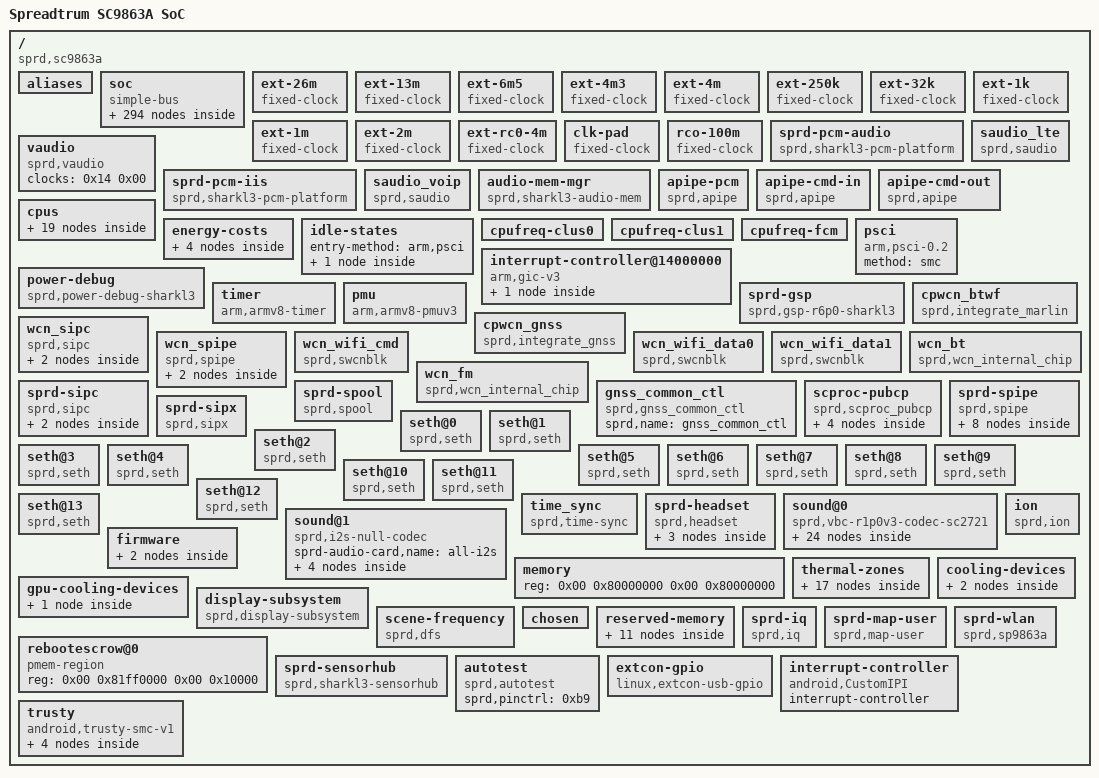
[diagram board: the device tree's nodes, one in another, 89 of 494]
/dts-v1/;

/ {
	interrupt-parent = < 0x01 >;
	#address-cells = < 0x02 >;
	#size-cells = < 0x02 >;
	cpuinfo_hardware = "UNISOC SC9863A";
	model = "Spreadtrum SC9863A SoC";
	compatible = "sprd,sc9863a";
	sprd,sc-id = "sp9863a 1000 1000";

	aliases {
		i2c0 = "/soc/ap-apb/i2c@70500000";
		i2c1 = "/soc/ap-apb/i2c@70600000";
		i2c2 = "/soc/ap-apb/i2c@70700000";
		i2c3 = "/soc/ap-apb/i2c@70800000";
		i2c4 = "/soc/ap-apb/i2c@70900000";
		i2c5 = "/soc/ap-apb/i2c@71500000";
		i2c6 = "/soc/ap-apb/i2c@71600000";
		i2c7 = "/soc/aon/i2c@40080000";
		spi0 = "/soc/ap-apb/spi@70a00000";
		spi1 = "/soc/ap-apb/spi@70b00000";
		spi2 = "/soc/ap-apb/spi@70c00000";
		spi3 = "/soc/ap-apb/spi@71400000";
		spi4 = "/soc/aon/spi@41800000";
		thm-sensor12 = "/soc/aon/test-sensor@12";
		seth0 = "/seth@0";
		seth1 = "/seth@1";
		seth2 = "/seth@2";
		seth3 = "/seth@3";
		seth4 = "/seth@4";
		seth5 = "/seth@5";
		seth6 = "/seth@6";
		seth7 = "/seth@7";
		seth8 = "/seth@8";
		seth9 = "/seth@9";
		seth10 = "/seth@10";
		seth11 = "/seth@11";
		seth12 = "/seth@12";
		seth13 = "/seth@13";
		cooling-device0 = "/cooling-devices/cluster0-cooling";
		cooling-device1 = "/cooling-devices/cluster1-cooling";
		gpu-cooling0 = "/gpu-cooling-devices/gpu-cooling0";
		thm-sensor11 = "/thermal-zones/cpu-thmzone";
		serial0 = "/soc/ap-apb/serial@70000000";
		serial1 = "/soc/ap-apb/serial@70100000";
	};

	soc {
		compatible = "simple-bus";
		#address-cells = < 0x02 >;
		#size-cells = < 0x02 >;
		ranges;
		phandle = < 0xbd >;

		modem-dbg-log@1000c000 {
			compatible = "sprd,dbg-log-sharkl3";
			reg = < 0x00 0x1000c000 0x00 0x4000 >;
			sprd,syscon-aon-apb = < 0x02 >;
			sprd,syscon-dsi-apb = < 0x03 >;
			sprd,syscon-pll-apb = < 0x04 >;
			sprd,ch-name = "TRAINING\0WTL\0MDAR\0TPIU\0DBUS\0WCN";
			sprd,ch-index = < 0x0f 0x01 0x00 0x02 0x03 0x04 >;
			sprd,dcfix;
			sprd,mm;
			status = "okay";
			clock-names = "serdes_eb\0src0\0src1\0src2";
			clocks = < 0x05 0x68 0x06 0x00 0x06 0x18 0x06 0x14 >;
			phandle = < 0xbe >;
		};

		syscon@20e00000 {
			compatible = "syscon";
			#syscon-cells = < 0x02 >;
			reg = < 0x00 0x20e00000 0x00 0x10000 >;
			phandle = < 0x0e >;
		};

		syscon@300e0000 {
			compatible = "syscon";
			#syscon-cells = < 0x02 >;
			reg = < 0x00 0x300e0000 0x00 0x10000 >;
			phandle = < 0x99 >;
		};

		syscon@300f0000 {
			compatible = "syscon";
			#syscon-cells = < 0x02 >;
			reg = < 0x00 0x300f0000 0x00 0x10000 >;
			phandle = < 0x52 >;
		};

		mailbox@400a0000 {
			compatible = "sprd,mailbox";
			reg = < 0x00 0x400a0000 0x00 0x8000 0x00 0x400a8000 0x00 0x8000 >;
			syscons = < 0x02 0x04 0x200000 >;
			syscon-names = "clk";
			interrupts = < 0x00 0x44 0x04 0x00 0x45 0x04 0x00 0x77 0x04 >;
			sprd,sensor = < 0x07 >;
			sprd,core-cnt = < 0x08 >;
			sprd,version = < 0x102 >;
			phandle = < 0xbf >;
		};

		syscon@40200000 {
			compatible = "syscon";
			#syscon-cells = < 0x02 >;
			reg = < 0x00 0x40200000 0x00 0x10000 >;
			phandle = < 0xc0 >;
		};

		syscon@402b0000 {
			compatible = "syscon";
			#syscon-cells = < 0x02 >;
			reg = < 0x00 0x402b0000 0x00 0x10000 >;
			phandle = < 0x07 >;
		};

		power-domain@402b0058 {
			compatible = "sprd,sharkl3-disp-domain";
			reg = < 0x00 0x402b0058 0x00 0x20 >;
			syscons = < 0x07 0x58 0x2000000 >;
			syscon-names = "power";
			#power-domain-cells = < 0x00 >;
			phandle = < 0x3f >;
		};

		syscon@402e0000 {
			compatible = "syscon";
			#syscon-cells = < 0x02 >;
			reg = < 0x00 0x402e0000 0x00 0x10000 >;
			phandle = < 0x02 >;
		};

		syscon@40350000 {
			compatible = "syscon";
			#syscon-cells = < 0x02 >;
			reg = < 0x00 0x40350000 0x00 0x3000 >;
			phandle = < 0x03 >;
		};

		syscon@40353000 {
			compatible = "syscon";
			#syscon-cells = < 0x02 >;
			reg = < 0x00 0x40353000 0x00 0x6000 >;
			phandle = < 0x04 >;
		};

		syscon@40359000 {
			compatible = "syscon";
			#syscon-cells = < 0x02 >;
			reg = < 0x00 0x40359000 0x00 0x3000 >;
			phandle = < 0x0f >;
		};

		syscon@4035c000 {
			compatible = "syscon";
			#syscon-cells = < 0x02 >;
			reg = < 0x00 0x4035c000 0x00 0x3000 >;
			phandle = < 0x54 >;
		};

		syscon@40363000 {
			compatible = "syscon";
			#syscon-cells = < 0x02 >;
			reg = < 0x00 0x40363000 0x00 0x3000 >;
			phandle = < 0x18 >;
		};

		syscon@40366000 {
			compatible = "syscon";
			#syscon-cells = < 0x02 >;
			reg = < 0x00 0x40366000 0x00 0x3000 >;
			phandle = < 0x9a >;
		};

		syscon@403a0000 {
			compatible = "syscon";
			#syscon-cells = < 0x02 >;
			reg = < 0x00 0x403a0000 0x00 0x10000 >;
			phandle = < 0x9b >;
		};

		syscon@60800000 {
			compatible = "syscon";
			#syscon-cells = < 0x02 >;
			reg = < 0x00 0x60800000 0x00 0x10000 >;
			phandle = < 0x4a >;
		};

		syscon@62000000 {
			compatible = "syscon";
			#syscon-cells = < 0x02 >;
			reg = < 0x00 0x62000000 0x00 0x10000 >;
			phandle = < 0x41 >;
		};

		syscon@71300000 {
			compatible = "syscon";
			#syscon-cells = < 0x02 >;
			reg = < 0x00 0x71300000 0x00 0x40000 >;
			phandle = < 0x0b >;
		};

		syscon@40500000 {
			compatible = "syscon";
			#syscon-cells = < 0x02 >;
			reg = < 0x00 0x40500000 0x00 0x10000 >;
			phandle = < 0x92 >;
		};

		syscon@40510000 {
			compatible = "syscon";
			#syscon-cells = < 0x02 >;
			reg = < 0x00 0x40510000 0x00 0x10000 >;
			phandle = < 0x93 >;
		};

		syscon@40520000 {
			compatible = "syscon";
			#syscon-cells = < 0x02 >;
			reg = < 0x00 0x40520000 0x00 0x10000 >;
			phandle = < 0x94 >;
		};

		syscon@40530000 {
			compatible = "syscon";
			#syscon-cells = < 0x02 >;
			reg = < 0x00 0x40530000 0x00 0x10000 >;
			phandle = < 0x95 >;
		};

		syscon@40540000 {
			compatible = "syscon";
			#syscon-cells = < 0x02 >;
			reg = < 0x00 0x40540000 0x00 0x10000 >;
			phandle = < 0x96 >;
		};

		syscon@40550000 {
			compatible = "syscon";
			#syscon-cells = < 0x02 >;
			reg = < 0x00 0x40550000 0x00 0x10000 >;
			phandle = < 0x97 >;
		};

		ap-apb {
			compatible = "simple-bus";
			#address-cells = < 0x01 >;
			#size-cells = < 0x01 >;
			ranges;

			serial@70000000 {
				compatible = "sprd,sc9863-uart\0sprd,sc9836-uart";
				reg = < 0x70000000 0x100 >;
				interrupts = < 0x00 0x02 0x04 >;
				clock-names = "enable\0uart\0source";
				clocks = < 0x08 0x0c 0x09 0x09 0x0a >;
				status = "okay";
				phandle = < 0xc1 >;
			};

			serial@70100000 {
				compatible = "sprd,sc9863-uart\0sprd,sc9836-uart";
				reg = < 0x70100000 0x100 >;
				interrupts = < 0x00 0x03 0x04 >;
				clock-names = "enable\0uart\0source";
				clocks = < 0x08 0x0d 0x09 0x0a 0x0a >;
				status = "okay";
				phandle = < 0xc2 >;
			};

			serial@70200000 {
				compatible = "sprd,sc9863-uart\0sprd,sc9836-uart";
				reg = < 0x70200000 0x100 >;
				interrupts = < 0x00 0x04 0x04 >;
				clock-names = "enable\0uart\0source";
				clocks = < 0x08 0x0e 0x09 0x0b 0x0a >;
				status = "disabled";
				phandle = < 0xc3 >;
			};

			serial@70300000 {
				compatible = "sprd,sc9863-uart\0sprd,sc9836-uart";
				reg = < 0x70300000 0x100 >;
				interrupts = < 0x00 0x05 0x04 >;
				clock-names = "enable\0uart\0source";
				clocks = < 0x08 0x0f 0x09 0x0c 0x0a >;
				status = "disabled";
				phandle = < 0xc4 >;
			};

			serial@70400000 {
				compatible = "sprd,sc9863-uart\0sprd,sc9836-uart";
				reg = < 0x70400000 0x100 >;
				interrupts = < 0x00 0x06 0x04 >;
				clock-names = "enable\0uart\0source";
				clocks = < 0x08 0x10 0x09 0x0d 0x0a >;
				status = "disabled";
				phandle = < 0xc5 >;
			};

			i2c@70500000 {
				compatible = "sprd,sharkl3-i2c";
				reg = < 0x70500000 0x1000 >;
				interrupts = < 0x00 0x0b 0x04 >;
				clock-names = "enable\0i2c\0source";
				clock-frequency = < 0x186a0 >;
				#address-cells = < 0x01 >;
				#size-cells = < 0x00 >;
				status = "disabled";
				syscon-names = "i2c_rst";
				syscons = < 0x0b 0x04 0x100 >;
				clocks = < 0x08 0x07 0x09 0x0e 0x0a >;
				phandle = < 0xc6 >;
			};

			i2c@70600000 {
				compatible = "sprd,sharkl3-i2c";
				reg = < 0x70600000 0x1000 >;
				interrupts = < 0x00 0x0c 0x04 >;
				clock-names = "enable\0i2c\0source";
				clock-frequency = < 0x186a0 >;
				#address-cells = < 0x01 >;
				#size-cells = < 0x00 >;
				status = "disabled";
				syscon-names = "i2c_rst";
				syscons = < 0x0b 0x04 0x200 >;
				clocks = < 0x08 0x08 0x09 0x0f 0x0a >;
				phandle = < 0xc7 >;
			};

			i2c@70700000 {
				compatible = "sprd,sharkl3-i2c";
				reg = < 0x70700000 0x1000 >;
				interrupts = < 0x00 0x0d 0x04 >;
				clock-names = "enable\0i2c\0source";
				clock-frequency = < 0x186a0 >;
				#address-cells = < 0x01 >;
				#size-cells = < 0x00 >;
				status = "disabled";
				syscon-names = "i2c_rst";
				syscons = < 0x0b 0x04 0x400 >;
				clocks = < 0x08 0x09 0x09 0x10 0x0a >;
				phandle = < 0xc8 >;
			};

			i2c@70800000 {
				compatible = "sprd,sharkl3-i2c";
				reg = < 0x70800000 0x1000 >;
				interrupts = < 0x00 0x0e 0x04 >;
				clock-names = "enable\0i2c\0source";
				clock-frequency = < 0x61a80 >;
				#address-cells = < 0x01 >;
				#size-cells = < 0x00 >;
				status = "disabled";
				syscon-names = "i2c_rst";
				syscons = < 0x0b 0x04 0x800 >;
				clocks = < 0x08 0x0a 0x09 0x11 0x0a >;
				phandle = < 0xc9 >;
			};

			i2c@70900000 {
				compatible = "sprd,sharkl3-i2c";
				reg = < 0x70900000 0x1000 >;
				interrupts = < 0x00 0x0f 0x04 >;
				clock-names = "enable\0i2c\0source";
				clock-frequency = < 0x186a0 >;
				#address-cells = < 0x01 >;
				#size-cells = < 0x00 >;
				status = "disabled";
				syscon-names = "i2c_rst";
				syscons = < 0x0b 0x04 0x1000 >;
				clocks = < 0x08 0x0b 0x09 0x12 0x0a >;
				phandle = < 0xca >;
			};

			spi@70a00000 {
				compatible = "sprd,sc9863-spi";
				reg = < 0x70a00000 0x1000 >;
				interrupts = < 0x00 0x07 0x04 >;
				#address-cells = < 0x01 >;
				#size-cells = < 0x00 >;
				status = "okay";
				clock-names = "enable\0spi\0source";
				clocks = < 0x08 0x04 0x09 0x15 0x06 0x03 >;
				phandle = < 0xcb >;
			};

			spi@70b00000 {
				compatible = "sprd,sc9863-spi";
				reg = < 0x70b00000 0x1000 >;
				interrupts = < 0x00 0x08 0x04 >;
				#address-cells = < 0x01 >;
				#size-cells = < 0x00 >;
				status = "disabled";
				clock-names = "enable\0spi\0source";
				clocks = < 0x08 0x05 0x09 0x16 0x06 0x03 >;
				phandle = < 0xcc >;
			};

			spi@70c00000 {
				compatible = "sprd,sc9863-spi";
				reg = < 0x70c00000 0x1000 >;
				interrupts = < 0x00 0x09 0x04 >;
				#address-cells = < 0x01 >;
				#size-cells = < 0x00 >;
				status = "disabled";
				clock-names = "enable\0spi\0source";
				clocks = < 0x08 0x06 0x09 0x17 0x06 0x03 >;
				phandle = < 0xcd >;
			};

			i2s@70d00000 {
				compatible = "sprd,i2s";
				reg = < 0x70d00000 0x100000 >;
				sprd,dai_name = "i2s_bt_sco0";
				sprd,hw_port = < 0x00 >;
				sprd,syscon-ap-apb = < 0x0b >;
				#sound-dai-cells = < 0x00 >;
				status = "okay";
				clock-names = "clk_iis0\0clk_twpll_128m\0clk_twpll_153m6";
				clocks = < 0x09 0x19 0x06 0x0a 0x06 0x0f >;
				sprd,config_type = "pcm";
				sprd,slave_timeout = < 0xf11 >;
				sprd,_hw_port = < 0x00 >;
				sprd,fs = < 0x1f40 >;
				sprd,bus_type = < 0x01 >;
				sprd,rtx_mode = < 0x03 >;
				sprd,byte_per_chan = < 0x01 >;
				sprd,slave_mode = < 0x00 >;
				sprd,lsb = < 0x00 >;
				sprd,lrck = < 0x00 >;
				sprd,low_for_left = < 0x01 >;
				sprd,clk_inv = < 0x00 >;
				sprd,pcm_short_frame = < 0x01 >;
				sprd,pcm_slot = < 0x01 >;
				sprd,pcm_cycle = < 0x01 >;
				sprd,tx_watermark = < 0x0c >;
				sprd,rx_watermark = < 0x14 >;
				phandle = < 0xae >;
			};

			spi@71400000 {
				compatible = "sprd,sc9863-spi";
				reg = < 0x71400000 0x1000 >;
				interrupts = < 0x00 0x13 0x04 >;
				#address-cells = < 0x01 >;
				#size-cells = < 0x00 >;
				status = "disabled";
				clock-names = "enable\0spi\0source";
				clocks = < 0x08 0x12 0x09 0x18 0x06 0x03 >;
				phandle = < 0xce >;
			};

			i2c@71500000 {
				compatible = "sprd,sharkl3-i2c";
				reg = < 0x71500000 0x1000 >;
				interrupts = < 0x00 0x74 0x04 >;
				clock-names = "enable\0i2c\0source";
				clock-frequency = < 0x186a0 >;
				#address-cells = < 0x01 >;
				#size-cells = < 0x00 >;
				status = "disabled";
				syscon-names = "i2c_rst";
				syscons = < 0x0b 0x04 0x100000 >;
				clocks = < 0x08 0x13 0x09 0x13 0x0a >;
				phandle = < 0xcf >;
			};

			i2c@71600000 {
				compatible = "sprd,sharkl3-i2c";
				reg = < 0x71600000 0x1000 >;
				interrupts = < 0x00 0x75 0x04 >;
				clock-names = "enable\0i2c\0source";
				clock-frequency = < 0x186a0 >;
				#address-cells = < 0x01 >;
				#size-cells = < 0x00 >;
				status = "disabled";
				syscon-names = "i2c_rst";
				syscons = < 0x0b 0x04 0x200000 >;
				clocks = < 0x08 0x14 0x09 0x14 0x0a >;
				phandle = < 0xd0 >;
			};
		};

		ap-ahb {
			compatible = "simple-bus";
			#address-cells = < 0x01 >;
			#size-cells = < 0x01 >;
			ranges;

			dma-controller@20100000 {
				compatible = "sprd,sharkl3-dma";
				reg = < 0x20100000 0x4000 >;
				interrupts = < 0x00 0x32 0x04 >;
				#dma-cells = < 0x01 >;
				#dma-channels = < 0x1c >;
				clock-names = "enable";
				clocks = < 0x0c 0x01 >;
				phandle = < 0x83 >;
			};

			usb@20200000 {
				compatible = "sprd,sharkl3-musb";
				reg = < 0x20200000 0x2000 >;
				interrupts = < 0x00 0x37 0x04 >;
				interrupt-names = "mc";
				clocks = < 0x0c 0x00 >;
				clock-names = "core_clk";
				phy-type = "usb20_sprd_phy";
				usb-phy = < 0x0d >;
				phy-names = "usb";
				dr-mode = "peripheral";
				phandle = < 0xd1 >;
			};

			hsphy@20e00000 {
				compatible = "sprd,sharkl3-phy";
				reg = < 0x20e00000 0x3030 >;
				reg-names = "phy_glb_regs";
				sprd,syscon-enable = < 0x02 >;
				sprd,syscon-apahb = < 0x0e >;
				sprd,syscon-anag4 = < 0x0f >;
				sprd,vdd-voltage = < 0x2e8a10 >;
				io-channels = < 0x10 0x1e 0x10 0x1f >;
				io-channel-names = "dp\0dm";
				#phy-cells = < 0x00 >;
				vdd-supply = < 0x11 >;
				extcon = < 0x12 >;
				phandle = < 0x0d >;
			};

			sdio@20600000 {
				compatible = "sprd,sdhc-r11p1";
				reg = < 0x20600000 0x1000 >;
				interrupts = < 0x00 0x3c 0x04 >;
				status = "okay";
				clock-names = "sdio_clk\0sdio_clk_source\0sdio_ahb_enable";
				clocks = < 0x13 0x21 0x14 0x02 0x0c 0x07 >;
				sprd,hs400es-dly = < 0x55 0x7f 0x38 0x38 >;
				sprd,hs400-dly = < 0x55 0xd3 0x35 0x35 >;
				sprd,hs200-dly = < 0x7f 0xcd 0xcd 0xcd >;
				sprd,ddr52-dly = < 0x32 0x23 0x18 0x18 >;
				sprd,mmchs-dly = < 0x00 0x35 0x35 0x35 >;
				vmmc-supply = < 0x15 >;
				voltage-ranges = < 0xbb8 0xbb8 >;
				bus-width = < 0x08 >;
				non-removable;
				cap-mmc-hw-reset;
				mmc-hs400-enhanced-strobe;
				mmc-hs400-1_8v;
				mmc-hs200-1_8v;
				mmc-ddr-1_8v;
				sprd,name = "sdio_emmc";
				sprd,sdio-adma;
				no-sdio;
				no-sd;
				phandle = < 0xd2 >;
			};

			sdio@20300000 {
				compatible = "sprd,sdhc-r11p1";
				reg = < 0x20300000 0x1000 >;
				interrupts = < 0x00 0x39 0x04 >;
				status = "okay";
				clock-names = "sdio_clk\0sdio_clk_source\0sdio_ahb_enable";
				clocks = < 0x13 0x1e 0x14 0x02 0x0c 0x04 >;
				sprd,sdr104-dly = < 0x7f 0x3d 0xc5 0xc5 >;
				sprd,sdr50-dly = < 0x7f 0x7f 0x4c 0x4c >;
				sprd,sdhs-dly = < 0x7f 0x32 0x83 0x83 >;
				vmmc-supply = < 0x16 >;
				vqmmc-supply = < 0x17 >;
				voltage-ranges = < 0xbb8 0xbb8 >;
				bus-width = < 0x04 >;
				sd-uhs-sdr104;
				sd-uhs-sdr50;
				sprd,name = "sdio_sd";
				sprd,sdio-adma;
				no-sdio;
				no-mmc;
				phandle = < 0xd3 >;
			};
		};

		aon {
			compatible = "simple-bus";
			#address-cells = < 0x01 >;
			#size-cells = < 0x01 >;
			ranges;

			audio-codec@40000000 {
				compatible = "sprd,sharkl3-audio-codec";
				reg = < 0x40000000 0x2000 >;
				interrupts = < 0x00 0x14 0x00 >;
				sprd,syscon-aon-apb = < 0x02 >;
				sprd,anlg-phy-g-syscon = < 0x18 >;
				phandle = < 0x3d >;
			};

			vbc@40020000 {
				compatible = "sprd,vbc-r1p0v3";
				#sound-dai-cells = < 0x01 >;
				reg = < 0x40020000 0x10000 >;
				sprd,clk-stable = < 0x402d0060 0x04 >;
				sprd,syscon-aon-apb = < 0x02 >;
				sprd,syscon-pmu-apb = < 0x07 >;
				sprd,dynamic-eq-support = < 0x00 >;
				sprd,vbc-iis-lr-invert = < 0x00 0x01 0x01 >;
				sprd,vbc-use-dma-type = < 0x00 0x00 0x00 0x00 >;
				sprd,vbc-use-ad01-only = < 0x01 >;
				sprd,iis_bt_fm_loop = < 0x03 0x04 >;
				pinctrl-names = "vbc_iis1_0\0ap_iis0_0\0ap_iis1_0\0tgdsp_iis0_0\0tgdsp_iis1_0\0pubcp_iis0_0\0vbc_iis1_3\0ap_iis0_3\0tgdsp_iis0_3\0tgdsp_iis1_3\0pubcp_iis0_3\0wcn_iis0_3\0vbc_iis1_4\0ap_iis0_4\0tgdsp_iis0_4\0tgdsp_iis1_4\0pubcp_iis0_4\0wcn_iis0_4\0iis_bt_fm_loop_3_4_enable\0iis_bt_fm_loop_3_4_disable";
				pinctrl-0 = < 0x19 >;
				pinctrl-1 = < 0x1a >;
				pinctrl-2 = < 0x1b >;
				pinctrl-3 = < 0x1c >;
				pinctrl-4 = < 0x1d >;
				pinctrl-5 = < 0x1e >;
				pinctrl-6 = < 0x1f >;
				pinctrl-7 = < 0x20 >;
				pinctrl-8 = < 0x21 >;
				pinctrl-9 = < 0x22 >;
				pinctrl-10 = < 0x23 >;
				pinctrl-11 = < 0x24 >;
				pinctrl-12 = < 0x25 >;
				pinctrl-13 = < 0x26 >;
				pinctrl-14 = < 0x27 >;
				pinctrl-15 = < 0x28 >;
				pinctrl-16 = < 0x29 >;
				pinctrl-17 = < 0x2a >;
				pinctrl-18 = < 0x2b >;
				pinctrl-19 = < 0x2c >;
				phandle = < 0xaa >;
			};

			dma-controller@40100000 {
				compatible = "sprd,sharkl3-dma";
				reg = < 0x40100000 0x4000 >;
				#dma-cells = < 0x01 >;
				#dma-channels = < 0x09 >;
				clock-names = "enable";
				clocks = < 0x05 0x32 >;
				phandle = < 0x82 >;
			};

			gpio@40210000 {
				compatible = "sprd,sharkl3-eic-debounce";
				reg = < 0x40210000 0x80 0x40370000 0x80 >;
				gpio-controller;
				#gpio-cells = < 0x02 >;
				interrupt-controller;
				#interrupt-cells = < 0x02 >;
				interrupts = < 0x00 0x25 0x04 >;
				phandle = < 0xba >;
			};

			gpio@40210080 {
				compatible = "sprd,sharkl3-eic-latch";
				reg = < 0x40210080 0x20 0x40370080 0x20 >;
				gpio-controller;
				#gpio-cells = < 0x02 >;
				interrupt-controller;
				#interrupt-cells = < 0x02 >;
				interrupts = < 0x00 0x25 0x04 >;
				phandle = < 0xd4 >;
			};

			gpio@402100a0 {
				compatible = "sprd,sharkl3-eic-async";
				reg = < 0x402100a0 0x20 0x403700a0 0x20 >;
				gpio-controller;
				#gpio-cells = < 0x02 >;
				interrupt-controller;
				#interrupt-cells = < 0x02 >;
				interrupts = < 0x00 0x25 0x04 >;
				phandle = < 0xd5 >;
			};

			gpio@402100c0 {
				compatible = "sprd,sharkl3-eic-sync";
				reg = < 0x402100c0 0x20 0x403700c0 0x20 >;
				gpio-controller;
				#gpio-cells = < 0x02 >;
				interrupt-controller;
				#interrupt-cells = < 0x02 >;
				interrupts = < 0x00 0x25 0x04 >;
				phandle = < 0xd6 >;
			};

			timer@40230000 {
				compatible = "sprd,syst-timer";
				reg = < 0x40230000 0x10 >;
				clocks = < 0x2d >;
				phandle = < 0xd7 >;
			};

			timer@40040000 {
				compatible = "sprd,sysfrt-timer";
				reg = < 0x40040000 0x10 >;
				clocks = < 0x2e >;
				phandle = < 0xd8 >;
			};

			timer@40050000 {
				compatible = "sprd,sharkl3-timer";
				reg = < 0x40050000 0x14 >;
				interrupts = < 0x00 0x1b 0x04 >;
				clocks = < 0x2e >;
			};

			timer@40050020 {
				compatible = "sprd,sharkl3-suspend-timer";
				reg = < 0x40050020 0x14 >;
				interrupts = < 0x00 0x1c 0x04 >;
				clocks = < 0x2e >;
			};

			efuse@40240000 {
				compatible = "sprd,sharkl3-efuse";
				reg = < 0x40240000 0x10000 >;
				clock-names = "enable";
				hwlocks = < 0x2f 0x08 >;
				clocks = < 0x05 0x0d >;
				phandle = < 0xd9 >;

				gthm-delta@21 {
					reg = < 0x21 0x04 >;
					bits = < 0x01 0x07 >;
					phandle = < 0x30 >;
				};

				cthm-sign@22 {
					reg = < 0x22 0x04 >;
					bits = < 0x00 0x01 >;
					phandle = < 0x31 >;
				};

				cthm-ratio@22 {
					reg = < 0x22 0x04 >;
					bits = < 0x01 0x07 >;
					phandle = < 0x32 >;
				};

				cthm-delta@23 {
					reg = < 0x23 0x04 >;
					bits = < 0x00 0x07 >;
					phandle = < 0x33 >;
				};

				wcn-alpha@14 {
					reg = < 0x14 0x04 >;
					phandle = < 0x9f >;
				};

				wcn-beta@18 {
					reg = < 0x18 0x04 >;
					phandle = < 0xa0 >;
				};

				wcn-gamma@1c {
					reg = < 0x1c 0x04 >;
					phandle = < 0xa1 >;
				};

				wcn-delta@20 {
					reg = < 0x20 0x04 >;
					phandle = < 0xa2 >;
				};

				dvfs-bin-dsu@a {
					reg = < 0x0a 0x04 >;
					bits = < 0x04 0x04 >;
					phandle = < 0x91 >;
				};

				dvfs-bin-cpu0@9 {
					reg = < 0x09 0x04 >;
					bits = < 0x00 0x04 >;
					phandle = < 0x8d >;
				};

				dvfs-bin-cpu1@9 {
					reg = < 0x09 0x04 >;
					bits = < 0x04 0x04 >;
					phandle = < 0x8f >;
				};
			};

			pwm@40260000 {
				compatible = "sprd,sharkl3-pwm\0sprd,sharkl5-pwm";
				reg = < 0x40260000 0x10000 >;
				clock-names = "clk_parent\0clk_pwm0\0clk_pwm0_eb\0clk_pwm1\0clk_pwm1_eb\0clk_pwm2\0clk_pwm2_eb";
				clocks = < 0x0a 0x13 0x0f 0x05 0x04 0x13 0x10 0x05 0x05 0x13 0x11 0x05 0x06 >;
				#pwm-cells = < 0x02 >;
				phandle = < 0xda >;
			};

			pinctrl@402a0000 {
				compatible = "sprd,sharkl3-pinctrl";
				reg = < 0x402a0000 0x10000 >;
				phandle = < 0xb9 >;

				iismtx-inf0-8 {
					pins = "SHARKL3_IIS_INF0_SYS_SEL";
					sprd,control = < 0x08 >;
					phandle = < 0x19 >;
				};

				iismtx-inf0-0 {
					pins = "SHARKL3_IIS_INF0_SYS_SEL";
					sprd,control = < 0x00 >;
					phandle = < 0x1a >;
				};

				iismtx-inf0-1 {
					pins = "SHARKL3_IIS_INF0_SYS_SEL";
					sprd,control = < 0x01 >;
					phandle = < 0x1b >;
				};

				iismtx-inf0-4 {
					pins = "SHARKL3_IIS_INF0_SYS_SEL";
					sprd,control = < 0x04 >;
					phandle = < 0x1c >;
				};

				iismtx-inf0-5 {
					pins = "SHARKL3_IIS_INF0_SYS_SEL";
					sprd,control = < 0x05 >;
					phandle = < 0x1d >;
				};

				iismtx-inf0-3 {
					pins = "SHARKL3_IIS_INF0_SYS_SEL";
					sprd,control = < 0x03 >;
					phandle = < 0x1e >;
				};

				iismtx-inf3-8 {
					pins = "SHARKL3_IIS_INF3_SYS_SEL";
					sprd,control = < 0x08 >;
					phandle = < 0x1f >;
				};

				iismtx-inf3-0 {
					pins = "SHARKL3_IIS_INF3_SYS_SEL";
					sprd,control = < 0x00 >;
					phandle = < 0x20 >;
				};

				iismtx-inf3-4 {
					pins = "SHARKL3_IIS_INF3_SYS_SEL";
					sprd,control = < 0x04 >;
					phandle = < 0x21 >;
				};

				iismtx-inf3-5 {
					pins = "SHARKL3_IIS_INF3_SYS_SEL";
					sprd,control = < 0x05 >;
					phandle = < 0x22 >;
				};

				iismtx-inf3-3 {
					pins = "SHARKL3_IIS_INF3_SYS_SEL";
					sprd,control = < 0x03 >;
					phandle = < 0x23 >;
				};

				iismtx-inf3-11 {
					pins = "SHARKL3_IIS_INF3_SYS_SEL";
					sprd,control = < 0x0b >;
					phandle = < 0x24 >;
				};

				iismtx-inf4-8 {
					pins = "SHARKL3_IIS_INF4_SYS_SEL";
					sprd,control = < 0x08 >;
					phandle = < 0x25 >;
				};

				iismtx-inf4-0 {
					pins = "SHARKL3_IIS_INF4_SYS_SEL";
					sprd,control = < 0x00 >;
					phandle = < 0x26 >;
				};

				iismtx-inf4-4 {
					pins = "SHARKL3_IIS_INF4_SYS_SEL";
					sprd,control = < 0x04 >;
					phandle = < 0x27 >;
				};

				iismtx-inf4-5 {
					pins = "SHARKL3_IIS_INF4_SYS_SEL";
					sprd,control = < 0x05 >;
					phandle = < 0x28 >;
				};

				iismtx-inf4-3 {
					pins = "SHARKL3_IIS_INF4_SYS_SEL";
					sprd,control = < 0x03 >;
					phandle = < 0x29 >;
				};

				iismtx-inf4-11 {
					pins = "SHARKL3_IIS_INF4_SYS_SEL";
					sprd,control = < 0x0b >;
					phandle = < 0x2a >;
				};

				iismtx-inf3-inf4-loop-1 {
					pins = "SHARKL3_IIS_INF4_INF3_LOOP";
					sprd,control = < 0x01 >;
					phandle = < 0x2b >;
				};

				iismtx-inf3-inf4-loop-0 {
					pins = "SHARKL3_IIS_INF4_INF3_LOOP";
					sprd,control = < 0x00 >;
					phandle = < 0x2c >;
				};
			};

			gpio-controller@402c0000 {
				compatible = "sprd,sharkl3-gpio-plus";
				reg = < 0x402c0000 0x1000 >;
				gpio-controller;
				#gpio-cells = < 0x02 >;
				interrupt-controller;
				#interrupt-cells = < 0x02 >;
				interrupts = < 0x00 0x82 0x04 >;
				phandle = < 0xa8 >;
			};

			gpu-thm@402f0000 {
				compatible = "sprd,sharkl3-thermal";
				reg = < 0x402f0000 0x10000 >;
				clock-names = "enable";
				clocks = < 0x05 0x20 >;
				#thermal-sensor-cells = < 0x01 >;
				sprd,algor_ver = < 0x02 >;
				nvmem-cells = < 0x30 >;
				nvmem-cell-names = "thm_delta_cal";
				phandle = < 0xb3 >;
			};

			cpu-thm@40390000 {
				compatible = "sprd,sharkl3-thermal";
				reg = < 0x40390000 0x10000 >;
				clock-names = "enable";
				clocks = < 0x05 0x20 >;
				#thermal-sensor-cells = < 0x01 >;
				sprd,algor_ver = < 0x01 >;
				nvmem-cells = < 0x31 0x32 0x33 >;
				nvmem-cell-names = "thm_sign_cal\0thm_ratio_cal\0thm_delta_cal";
				phandle = < 0xaf >;
			};

			test-sensor@12 {
				compatible = "sprd,virtual-thermal";
				#thermal-sensor-cells = < 0x01 >;
				sensor-names = "test-thmzone";
				phandle = < 0xb4 >;
			};

			hwspinlock@40060000 {
				compatible = "sprd,hwspinlock-r3p0";
				reg = < 0x40060000 0x10000 >;
				#hwlock-cells = < 0x01 >;
				clock-names = "enable";
				clocks = < 0x05 0x16 >;
				phandle = < 0x2f >;
			};

			i2c@40080000 {
				compatible = "sprd,sharkl3-hw-i2c";
				reg = < 0x40080000 0x1000 >;
				interrupts = < 0x00 0x22 0x04 >;
				clock-names = "enable\0i2c\0source\0clk_hw_i2c";
				clock-frequency = < 0x61a80 >;
				#address-cells = < 0x01 >;
				#size-cells = < 0x00 >;
				status = "okay";
				phandle = < 0xdb >;

				regulator@60 {
					compatible = "fcs,fan53555";
					reg = < 0x60 >;
					regulator-name = "fan53555";
					regulator-min-microvolt = < 0x93378 >;
					regulator-max-microvolt = < 0x1587b8 >;
					regulator-ramp-delay = < 0xfa00 >;
					regulator-always-on;
					fcs,suspend-voltage-selector = < 0x01 >;
					phandle = < 0x84 >;
				};
			};

			hwdvfs@40300000 {
				compatible = "sprd,sharkl3-hwdvfs";
				sprd,syscon-enable = < 0x02 >;
				sprd,anlg-phy-g4-ctrl = < 0x0f >;
				sprd,syscon-pmu-apb = < 0x07 >;
				reg = < 0x40300000 0x1000 >;
				interrupts = < 0x00 0x79 0x04 >;
				phandle = < 0xdc >;
			};

			sprd-swdvfs {
				compatible = "sprd,sharkl3-swdvfs";
				phandle = < 0xdd >;
			};

			watchdog@40310000 {
				compatible = "sprd,wdt-r2p0-fiq-sharkl3";
				reg = < 0x40310000 0x1000 >;
				interrupts = < 0x00 0x7c 0x04 >;
				timeout-sec = < 0x1e >;
				clock-names = "enable\0rtc_enable";
				clocks = < 0x05 0x26 0x05 0x42 >;
			};

			djtag@40340000 {
				compatible = "sprd,djtag";
				reg = < 0x40340000 0x1000 >;
				syscon-names = "soft_rst";
				syscons = < 0x02 0x130 0x80 >;
				clock-names = "enable\0tck";
				clocks = < 0x05 0x30 0x05 0x29 >;
				hwlocks = < 0x2f 0x0a >;
				hwlock-names = "djtag";
				#address-cells = < 0x01 >;
				#size-cells = < 0x00 >;
				phandle = < 0xde >;

				aon-busmonitor@3 {
					compatible = "sprd,sharkl3-busmonitor";
					interrupts = < 0x00 0x5c 0x04 >;
					reg = < 0x03 >;
					sprd,bm-num = < 0x07 >;
					sprd,bm-name = "AP\0WTLCP\0PUBCP\0SP\0DMA\0EAXI\0WCN";
					sprd,bm-type = < 0x01 0x01 0x01 0x01 0x01 0x01 0x01 >;
					sprd,bm-dap = < 0x00 0x02 0x01 0x03 0x04 0x05 0x09 >;
					sprd,bm-config = < 0x00 0x01 0x01 0x00 0x01 0x01 0x00 0x01 0x01 0x00 0x01 0x01 0x00 0x01 0x01 0x00 0x01 0x01 0x00 0x01 0x01 >;
					sprd,bm-id = < 0x00 0x00 0x00 0x00 0x00 0x00 0x00 0x00 0x00 0x00 0x00 0x00 0x00 0x00 0x00 0x00 0x00 0x00 0x00 0x00 0x00 >;
					sprd,bm-ranges = < 0x00 0x00 0x00 0x00 0x00 0x00 0x00 0x00 0x00 0x00 0x00 0x00 0x00 0x00 >;
				};

				apcpu-busmonitor@7 {
					compatible = "sprd,sharkl3-busmonitor";
					interrupts = < 0x00 0x57 0x04 >;
					reg = < 0x07 >;
					sprd,bm-num = < 0x02 >;
					sprd,bm-name = "ACE\0AP";
					sprd,bm-type = < 0x01 0x01 >;
					sprd,bm-dap = < 0x01 0x02 >;
					sprd,bm-config = < 0x00 0x01 0x01 0x00 0x01 0x01 >;
					sprd,bm-id = < 0x00 0x00 0x00 0x00 0x00 0x00 >;
					sprd,bm-ranges = < 0x00 0x00 0x00 0x00 >;
				};
			};

			spi@41800000 {
				compatible = "sprd,sharkl3-adi";
				reg = < 0x41800000 0x200000 >;
				#address-cells = < 0x01 >;
				#size-cells = < 0x00 >;
				sprd,hw-channels = < 0x21 0x8c20 0x23 0x8cc4 0x24 0x8cd0 0x13 0x8c44 0x14 0x8c44 0x15 0x8c44 0x16 0x8c44 >;
				phandle = < 0xdf >;

				pmic@0 {
					compatible = "sprd,sc2721";
					reg = < 0x00 >;
					spi-max-frequency = < 0x18cba80 >;
					interrupts = < 0x00 0x26 0x04 >;
					interrupt-controller;
					#interrupt-cells = < 0x02 >;
					#address-cells = < 0x01 >;
					#size-cells = < 0x00 >;
					phandle = < 0x34 >;

					watchdog@40 {
						compatible = "sprd,sc2721-wdt\0sprd,sc27xx-wdt";
						reg = < 0x40 >;
						phandle = < 0xe0 >;
					};

					led-controller@180 {
						compatible = "sprd,sc27xx-bltc\0sprd,sc2721-bltc";
						#address-cells = < 0x01 >;
						#size-cells = < 0x00 >;
						reg = < 0x180 >;

						led@0 {
							label = "red";
							reg = < 0x00 >;
						};

						led@1 {
							label = "green";
							reg = < 0x01 >;
						};

						led@2 {
							label = "blue";
							reg = < 0x02 >;
						};
					};

					rtc@200 {
						compatible = "sprd,sc27xx-rtc\0sprd,sc2721-rtc";
						reg = < 0x200 >;
						interrupt-parent = < 0x34 >;
						interrupts = < 0x01 0x04 >;
					};

					gpio-controller@280 {
						compatible = "sprd,sc27xx-eic\0sprd,sc2721-eic";
						reg = < 0x280 >;
						interrupts = < 0x04 0x04 >;
						interrupt-parent = < 0x34 >;
						gpio-controller;
						#gpio-cells = < 0x02 >;
						interrupt-controller;
						#interrupt-cells = < 0x02 >;
						phandle = < 0x3b >;
					};

					flash@2a8 {
						compatible = "sprd,sc27xx-flash\0sprd,sc2721-flash";
						reg = < 0x2a8 >;
						status = "disabled";
						phandle = < 0xe1 >;
					};

					efuse@300 {
						compatible = "sprd,sc27xx-efuse\0sprd,sc2721-efuse";
						reg = < 0x300 >;
						#address-cells = < 0x01 >;
						#size-cells = < 0x01 >;
						hwlocks = < 0x2f 0x0c >;

						calib@6 {
							reg = < 0x06 0x02 >;
							phandle = < 0x3c >;
						};

						calib@24 {
							reg = < 0x24 0x02 >;
							phandle = < 0x38 >;
						};

						calib@26 {
							reg = < 0x26 0x02 >;
							phandle = < 0x39 >;
						};

						calib@d1 {
							reg = < 0x1a 0x02 >;
							phandle = < 0x35 >;
						};

						calib@d2 {
							reg = < 0x1a 0x02 >;
							phandle = < 0x36 >;
						};

						calib@0 {
							reg = < 0x00 0x02 >;
							phandle = < 0xa4 >;
						};

						calib@28 {
							reg = < 0x28 0x02 >;
							phandle = < 0xa5 >;
						};

						calib@2c {
							reg = < 0x2c 0x02 >;
							phandle = < 0xa6 >;
						};

						calib@12 {
							reg = < 0x18 0x02 >;
							phandle = < 0x3a >;
						};
					};

					typec@380 {
						compatible = "sprd,sc27xx-typec\0sprd,sc2721-typec";
						interrupt-parent = < 0x34 >;
						interrupts = < 0x0a 0x04 >;
						reg = < 0x380 >;
						mode = < 0x02 >;
						nvmem-cells = < 0x35 0x36 >;
						nvmem-cell-names = "typec_cc1_cal\0typec_cc2_cal";
						status = "okay";
						phandle = < 0xe2 >;
					};

					adc@400 {
						compatible = "sprd,sc27xx-adc\0sprd,sc2721-adc";
						reg = < 0x400 >;
						vref-supply = < 0x37 >;
						interrupt-parent = < 0x34 >;
						interrupts = < 0x00 0x04 >;
						#io-channel-cells = < 0x01 >;
						hwlocks = < 0x2f 0x04 >;
						nvmem-cells = < 0x38 0x39 >;
						nvmem-cell-names = "big_scale_calib\0small_scale_calib";
						phandle = < 0x10 >;
					};

					fchg@900 {
						compatible = "sprd,sc27xx-fast-chg\0sprd,sc2721-fast-charger";
						reg = < 0x900 >;
						interrupt-parent = < 0x34 >;
						interrupts = < 0x05 0x04 >;
						nvmem-cell-names = "fchg_cur_calib";
						nvmem-cells = < 0x3a >;
						status = "disabled";
						phandle = < 0xe3 >;
					};

					fgu@a00 {
						compatible = "sprd,sc27xx-fgu\0sprd,sc2720-fgu\0sprd,sc2721-fgu";
						reg = < 0xa00 >;
						bat-detect-gpio = < 0x3b 0x09 0x00 >;
						nvmem-cell-names = "fgu_calib";
						nvmem-cells = < 0x3c >;
						io-channels = < 0x10 0x00 0x10 0x0e >;
						io-channel-names = "bat-temp\0charge-vol";
						interrupt-parent = < 0x34 >;
						interrupts = < 0x03 0x04 >;
						phandle = < 0xe4 >;
					};

					syscon@c00 {
						compatible = "sprd,sc27xx-syscon";
						reg = < 0xc00 0xecc 0xec0 >;
					};

					audio-codec@700 {
						compatible = "sprd,sc2721-audio-codec\0sprd,sc27xx-audio-codec";
						#sound-dai-cells = < 0x01 >;
						reg = < 0x700 >;
						interrupts = < 0x06 0x00 >;
						sprd,syscon-pmu-apb = < 0x07 >;
						status = "okay";
						digital-codec = < 0x3d >;
						phandle = < 0xab >;
					};

					power-controller@c00 {
						compatible = "sprd,sc27xx-regulator\0sprd,sc2721-regulator";

						DCDC_CPU {
							regulator-name = "vddcpu";
							regulator-min-microvolt = < 0x61a80 >;
							regulator-max-microvolt = < 0x1e74e0 >;
							regulator-ramp-delay = < 0x61a8 >;
							regulator-always-on;
							phandle = < 0x89 >;
						};

						DCDC_CORE {
							regulator-name = "vddcore";
							regulator-min-microvolt = < 0x61a80 >;
							regulator-max-microvolt = < 0x1e74e0 >;
							regulator-ramp-delay = < 0x61a8 >;
							regulator-always-on;
							phandle = < 0xe5 >;
						};

						DCDC_MEM {
							regulator-name = "vddmem";
							regulator-min-microvolt = < 0x61a80 >;
							regulator-max-microvolt = < 0x36e24b >;
							regulator-ramp-delay = < 0x61a8 >;
							regulator-always-on;
							phandle = < 0xe6 >;
						};

						DCDC_GEN {
							regulator-name = "vddgen";
							regulator-min-microvolt = < 0x927c0 >;
							regulator-max-microvolt = < 0x39ef8b >;
							regulator-ramp-delay = < 0x61a8 >;
							regulator-always-on;
							phandle = < 0xe7 >;
						};

						LDO_VDDCAMA {
							regulator-name = "vddcama";
							regulator-min-microvolt = < 0x124f80 >;
							regulator-max-microvolt = < 0x393870 >;
							regulator-ramp-delay = < 0x61a8 >;
							phandle = < 0xe8 >;
						};

						LDO_VDDCAMMOT {
							regulator-name = "vddcammot";
							regulator-min-microvolt = < 0x124f80 >;
							regulator-max-microvolt = < 0x393870 >;
							regulator-ramp-delay = < 0x61a8 >;
							phandle = < 0xe9 >;
						};

						LDO_VDDSIM2 {
							regulator-name = "vddsim2";
							regulator-min-microvolt = < 0x124f80 >;
							regulator-max-microvolt = < 0x393870 >;
							regulator-ramp-delay = < 0x61a8 >;
							phandle = < 0xea >;
						};

						LDO_VDDEMMCCORE {
							regulator-name = "vddemmccore";
							regulator-min-microvolt = < 0x124f80 >;
							regulator-max-microvolt = < 0x393870 >;
							regulator-ramp-delay = < 0x61a8 >;
							phandle = < 0x15 >;
						};

						LDO_VDDSDCORE {
							regulator-name = "vddsdcore";
							regulator-min-microvolt = < 0x124f80 >;
							regulator-max-microvolt = < 0x393870 >;
							regulator-ramp-delay = < 0x61a8 >;
							phandle = < 0x16 >;
						};

						LDO_VDDSDIO {
							regulator-name = "vddsdio";
							regulator-min-microvolt = < 0x124f80 >;
							regulator-max-microvolt = < 0x393870 >;
							regulator-ramp-delay = < 0x61a8 >;
							phandle = < 0x17 >;
						};

						LDO_VDD28 {
							regulator-name = "vdd28";
							regulator-min-microvolt = < 0x124f80 >;
							regulator-max-microvolt = < 0x393870 >;
							regulator-ramp-delay = < 0x61a8 >;
							regulator-always-on;
							phandle = < 0x37 >;
						};

						LDO_VDDWIFIPA {
							regulator-name = "vddwifipa";
							regulator-min-microvolt = < 0x124f80 >;
							regulator-max-microvolt = < 0x393870 >;
							regulator-ramp-delay = < 0x61a8 >;
							phandle = < 0x9e >;
						};

						LDO_VDDDCXO {
							regulator-name = "vdddcxo";
							regulator-min-microvolt = < 0x124f80 >;
							regulator-max-microvolt = < 0x393870 >;
							regulator-ramp-delay = < 0x61a8 >;
							regulator-always-on;
							phandle = < 0xeb >;
						};

						LDO_VDDUSB33 {
							regulator-name = "vddusb33";
							regulator-min-microvolt = < 0x124f80 >;
							regulator-max-microvolt = < 0x393870 >;
							regulator-ramp-delay = < 0x61a8 >;
							phandle = < 0x11 >;
						};

						LDO_VDDCAMD {
							regulator-name = "vddcamd";
							regulator-min-microvolt = < 0xf5aaa >;
							regulator-max-microvolt = < 0x16e360 >;
							regulator-ramp-delay = < 0x61a8 >;
							phandle = < 0xec >;
						};

						LDO_VDDCON {
							regulator-name = "vddcon";
							regulator-min-microvolt = < 0x10e14a >;
							regulator-max-microvolt = < 0x186a00 >;
							regulator-ramp-delay = < 0x61a8 >;
							phandle = < 0x9d >;
						};

						LDO_VDDCAMIO {
							regulator-name = "vddcamio";
							regulator-min-microvolt = < 0x10e14a >;
							regulator-max-microvolt = < 0x1cfde0 >;
							regulator-ramp-delay = < 0x61a8 >;
							phandle = < 0xed >;
						};

						LDO_VDD18 {
							regulator-name = "vdd18";
							regulator-min-microvolt = < 0x10e14a >;
							regulator-max-microvolt = < 0x1cfde0 >;
							regulator-ramp-delay = < 0x61a8 >;
							phandle = < 0xee >;
						};

						LDO_VDDRF18 {
							regulator-name = "vddrf18";
							regulator-min-microvolt = < 0x10e14a >;
							regulator-max-microvolt = < 0x1cfde0 >;
							regulator-ramp-delay = < 0x61a8 >;
							phandle = < 0xef >;
						};

						LDO_VDDRF125 {
							regulator-name = "vddrf125";
							regulator-min-microvolt = < 0x10e14a >;
							regulator-max-microvolt = < 0x155cc0 >;
							regulator-ramp-delay = < 0x61a8 >;
							phandle = < 0xf0 >;
						};

						LDO_VDDLDOMEM {
							regulator-name = "vddldomem";
							regulator-min-microvolt = < 0x10e14a >;
							regulator-max-microvolt = < 0x155cc0 >;
							regulator-ramp-delay = < 0x61a8 >;
							phandle = < 0xf1 >;
						};

						LDO_VDDKPLED {
							regulator-name = "vddkpled";
							regulator-min-microvolt = < 0x124f80 >;
							regulator-max-microvolt = < 0x393870 >;
							regulator-ramp-delay = < 0x61a8 >;
							phandle = < 0xf2 >;
						};
					};

					poweroff@c20 {
						compatible = "sprd,sc27xx-poweroff\0sprd,sc2721-poweroff";
						reg = < 0xc20 >;
					};

					vibrator@eb4 {
						compatible = "sprd,sc27xx-vibrator\0sprd,sc2721-vibrator";
						reg = < 0xeb4 >;
					};

					hw_reset@eec {
						compatible = "sprd,sc27xx-7sreset\0sprd,sc2721-7sreset";
						reg = < 0xf1c 0xeec >;
					};
				};
			};
		};

		mm {
			compatible = "simple-bus";
			#address-cells = < 0x01 >;
			#size-cells = < 0x01 >;
			ranges;

			cam-domain {
				compatible = "sprd,cam-domain";
				syscons = < 0x07 0x1c 0x1000000 0x07 0x1c 0x2000000 0x07 0xbc 0xf8000000 0x07 0x6ec 0x80000 0x02 0x50 0x1f3f8 >;
				syscon-names = "shutdown_en\0force_shutdown\0pwr_status0\0bus_status0\0init_dis_bits";
				clock-names = "clk_cphy_cfg_gate_eb\0clk_mm_eb\0clk_mm_ahb\0clk_mm_ahb_parent\0clk_mm_emc\0clk_mm_emc_parent";
				clocks = < 0x05 0x66 0x05 0x19 0x13 0x2a 0x06 0x0f 0x13 0x29 0x06 0x08 >;
				phandle = < 0xf3 >;
			};

			gpu@60000000 {
				compatible = "sprd,rogue";
				reg = < 0x60000000 0x100000 >;
				syscons = < 0x07 0x20 0x2000000 0x07 0x124 0x2000000 0x07 0x124 0x1000000 0x02 0x50 0x01 0x07 0xbc 0x7c00000 0x07 0x128 0x3e0 >;
				syscon-names = "top_force_shutdown\0core_force_shutdown\0core_auto_shutdown\0clk_gpu_eb\0gpu_top_state\0gpu_core_state";
				interrupts = < 0x00 0x27 0x04 >;
				operating-points = < 0x3e800 0x00 0x5dc00 0x00 0x86470 0x00 >;
				sprd,dvfs-lists = < 0x3e800 0x00 0x05 0x01 0x5dc00 0x00 0x07 0x01 0x86470 0x00 0x09 0x01 >;
				sprd,dvfs-default = < 0x00 >;
				sprd,dvfs-scene-extreme = < 0x02 >;
				sprd,dvfs-scene-high = < 0x01 >;
				sprd,dvfs-scene-medium = < 0x01 >;
				sprd,dvfs-scene-low = < 0x00 >;
				sprd,dvfs-range-max = < 0x02 >;
				sprd,dvfs-range-min = < 0x00 >;
				clocks = < 0x05 0x4c 0x13 0x27 0x13 0x28 0x06 0x0f 0x06 0x03 0x06 0x09 0x06 0x0c 0x06 0x02 0x06 0x08 0x06 0x17 >;
				phandle = < 0xf4 >;
			};

			dpu@63000000 {
				compatible = "sprd,display-processor";
				reg = < 0x63000000 0x1000 >;
				interrupts = < 0x00 0x2e 0x04 >;
				status = "okay";
				iommus = < 0x3e >;
				power-domains = < 0x3f >;
				dma-coherent;
				sprd,ip = "dpu-r2p0";
				sprd,soc = "sharkl3";
				syscons = < 0x02 0x0c 0x100000 >;
				syscon-names = "reset";
				clock-names = "clk_src_128m\0clk_src_153m6\0clk_src_192m\0clk_src_256m\0clk_src_384m\0clk_dpu_core\0clk_dpu_dpi\0clk_aon_apb_disp_eb";
				clocks = < 0x06 0x0a 0x06 0x0f 0x06 0x03 0x06 0x09 0x06 0x02 0x13 0x22 0x13 0x23 0x05 0x4d >;
				phandle = < 0xf5 >;

				port {
					phandle = < 0xb6 >;

					endpoint {
						remote-endpoint = < 0x40 >;
						phandle = < 0x46 >;
					};
				};
			};

			gsp@63000000 {
				compatible = "sprd,gsp-core";
				reg = < 0x63000000 0x2000 >;
				core-id = < 0x00 >;
				kcfg-num = < 0x10 >;
				interrupts = < 0x00 0x33 0x04 >;
				iommus = < 0x3e >;
				clock-names = "clk_dpu_core_src\0clk_dpu_core\0clk_aon_apb_disp_eb";
				clocks = < 0x06 0x02 0x13 0x22 0x05 0x4d >;
				phandle = < 0x98 >;
			};

			iommu@63000800 {
				compatible = "sprd,iommuex-dispc";
				reg = < 0x63000800 0x80 >;
				sprd,iova-base = < 0x30000000 >;
				sprd,iova-size = < 0x10000000 >;
				reg_name = "mmu_reg";
				status = "okay";
				#iommu-cells = < 0x00 >;
				phandle = < 0x3e >;
			};

			video-codec@62200000 {
				compatible = "sprd,sharkl3-vsp";
				reg = < 0x62200000 0xc000 >;
				interrupts = < 0x00 0x2b 0x04 >;
				syscons = < 0x41 0x04 0x0c 0x07 0x30 0x2000000 0x07 0x30 0x1000000 0x07 0x128 0x1f 0x02 0x04 0x4000 >;
				syscon-names = "reset\0pmu_vsp_force_shutdown\0pmu_vsp_auto_shutdown\0pmu_pwr_status\0vsp_domain_eb";
				iommus = < 0x42 >;
				status = "okay";
				clock-names = "clk_mm_eb\0clk_ahb_gate_vsp_eb\0clk_axi_gate_vsp\0clk_vsp_ahb_mmu_eb\0clk_ahb_vsp\0clk_ahb_vsp_parent\0clk_emc_vsp\0clk_emc_vsp_parent\0clk_src_76m8\0clk_src_128m\0clk_src_256m\0clk_src_307m2\0clk_src_384m\0clk_vsp";
				clocks = < 0x05 0x2c 0x05 0x51 0x43 0x00 0x43 0x01 0x13 0x34 0x06 0x0f 0x13 0x33 0x06 0x19 0x06 0x10 0x06 0x0a 0x06 0x09 0x06 0x0c 0x06 0x02 0x13 0x35 >;
				phandle = < 0xf6 >;
			};

			iommu@62200000 {
				compatible = "sprd,iommuex-vsp";
				reg = < 0x62200000 0x80 >;
				sprd,iova-base = < 0x20000000 >;
				sprd,iova-size = < 0x10000000 >;
				reg_name = "mmu_reg";
				status = "okay";
				#iommu-cells = < 0x00 >;
				phandle = < 0x42 >;
			};

			jpeg-codec@62300000 {
				compatible = "sprd,sharkl3-jpg";
				reg = < 0x62300000 0x8000 >;
				interrupts = < 0x00 0x2a 0x04 >;
				syscons = < 0x41 0x04 0x20 0x02 0x00 0x2000000 >;
				syscon-names = "reset\0aon_apb_eb";
				iommus = < 0x44 >;
				status = "okay";
				clock-names = "jpg_domain_eb\0clk_aon_jpg_emc_eb\0jpg_dev_eb\0jpg_ckg_eb\0clk_ahb_vsp\0clk_ahb_vsp_parent\0clk_emc_vsp\0clk_emc_vsp_parent\0clk_src_256m\0clk_src_307m2\0jpg_clk";
				clocks = < 0x05 0x2c 0x05 0x51 0x43 0x00 0x43 0x02 0x13 0x34 0x06 0x0f 0x13 0x33 0x06 0x19 0x06 0x09 0x06 0x0c 0x13 0x2e >;
				phandle = < 0xf7 >;
			};

			iommu@62300300 {
				compatible = "sprd,iommuex-jpg";
				reg = < 0x62300300 0x400 >;
				sprd,iova-base = < 0x70000000 >;
				sprd,iova-size = < 0x10000000 >;
				reg_name = "mmu_reg";
				status = "okay";
				#iommu-cells = < 0x00 >;
				phandle = < 0x44 >;
			};

			dsi@63100000 {
				compatible = "sprd,dsi-host";
				reg = < 0x63100000 0x1000 >;
				interrupts = < 0x00 0x30 0x04 0x00 0x31 0x04 >;
				status = "okay";
				power-domains = < 0x3f >;
				sprd,ip = "sprd,dsi-ctrl\0r3p0";
				sprd,soc = "sharkl3";
				syscons = < 0x02 0x628 0x04 >;
				syscon-names = "reset";
				clock-names = "clk_aon_apb_disp_eb";
				clocks = < 0x05 0x4d >;
				#address-cells = < 0x01 >;
				#size-cells = < 0x00 >;
				phandle = < 0xf8 >;

				ports {
					#address-cells = < 0x01 >;
					#size-cells = < 0x00 >;

					port@0 {
						reg = < 0x00 >;

						endpoint {
							remote-endpoint = < 0x45 >;
							phandle = < 0x49 >;
						};
					};

					port@1 {
						reg = < 0x01 >;

						endpoint {
							remote-endpoint = < 0x46 >;
							phandle = < 0x40 >;
						};
					};
				};

				panel {
					compatible = "sprd,generic-mipi-panel";
					#address-cells = < 0x01 >;
					#size-cells = < 0x00 >;
					reg = < 0x00 >;
					phandle = < 0xf9 >;

					port@1 {
						reg = < 0x01 >;

						endpoint {
							remote-endpoint = < 0x47 >;
							phandle = < 0x48 >;
						};
					};
				};
			};

			dphy {
				compatible = "sprd,dsi-phy";
				#address-cells = < 0x01 >;
				#size-cells = < 0x00 >;
				reg = < 0x63100000 0x1000 >;
				status = "okay";
				sprd,ip = "sprd,megacores-sharkle";
				sprd,soc = "sharkl3";
				syscons = < 0x02 0xb0 0x1800000 0x02 0x24 0x8000 0x02 0x24 0x4000 0x02 0x24 0x8000000 >;
				syscon-names = "enable\0power_small\0power_large\0power_iso";
				phandle = < 0xfa >;

				port@0 {
					reg = < 0x00 >;

					endpoint {
						remote-endpoint = < 0x48 >;
						phandle = < 0x47 >;
					};
				};

				port@1 {
					reg = < 0x01 >;

					endpoint {
						remote-endpoint = < 0x49 >;
						phandle = < 0x45 >;
					};
				};
			};

			mipi-csi-phy0 {
				compatible = "sprd,mipi-csi-phy";
				sprd,phyid = < 0x00 >;
				sprd,phyname = "2p2";
				status = "disabled";
				phandle = < 0xfb >;
			};

			mipi-csi-phy1 {
				compatible = "sprd,mipi-csi-phy";
				sprd,phyid = < 0x01 >;
				sprd,phyname = "4lane";
				status = "disabled";
				phandle = < 0xfc >;
			};

			mipi-csi-phy2 {
				compatible = "sprd,mipi-csi-phy";
				sprd,phyid = < 0x02 >;
				sprd,phyname = "2lane";
				status = "disabled";
				phandle = < 0xfd >;
			};

			mipi-csi-phy0-s {
				compatible = "sprd,mipi-csi-phy";
				sprd,phyid = < 0x03 >;
				sprd,phyname = "2p2_m";
				status = "disabled";
				phandle = < 0xfe >;
			};

			mipi-csi-phy0-m {
				compatible = "sprd,mipi-csi-phy";
				sprd,phyid = < 0x04 >;
				sprd,phyname = "2p2_s";
				status = "disabled";
				phandle = < 0xff >;
			};

			mipi-csi-phy0-m1 {
				compatible = "sprd,mipi-csi-phy";
				sprd,phyid = < 0x04 >;
				sprd,phyname = "2p2_s";
				status = "disabled";
				phandle = < 0x100 >;
			};

			dcam@60a00000 {
				compatible = "sprd,sharkl3-cam";
				reg = < 0x60a00000 0x1000 0x60a01000 0x1000 0x60a02000 0x1000 0x60a03000 0x1000 >;
				reg_name = "dcam0_reg\0dcam1_reg\0dcam2_reg\0axi_ctrl_reg";
				interrupts = < 0x00 0x2d 0x04 0x00 0x9e 0x04 0x00 0x9f 0x04 >;
				interrupts_name = "dcam0\0dcam1\0dcam2";
				syscons = < 0x4a 0x04 0x40 0x4a 0x04 0x04 0x4a 0x04 0x08 0x4a 0x04 0x10 >;
				syscon-names = "dcam_all_reset\0dcam0_reset\0dcam1_reset\0dcam2_reset";
				sprd,aon-apb-syscon = < 0x02 >;
				sprd,cam-ahb-syscon = < 0x4a >;
				sprd,isp = < 0x4b >;
				sprd,dcam-count = < 0x03 >;
				sprd,project-id = < 0x00 >;
				iommus = < 0x4c >;
				status = "okay";
				clock-names = "dcam_eb\0dcam_axi_eb\0clk_cphy_cfg_gate_eb\0clk_mm_eb\0clk_mm_ahb\0clk_mm_ahb_parent\0clk_mm_emc\0clk_mm_emc_parent\0dcam_clk\0dcam_clk_256m\0dcam_clk_307m2\0dcam_clk_384m\0dcam_clk_parent\0dcam_bpc_clk\0dcam_bpc_clk_parent";
				clocks = < 0x4d 0x01 0x4d 0x06 0x05 0x66 0x05 0x19 0x13 0x2a 0x06 0x0f 0x13 0x29 0x06 0x08 0x13 0x2c 0x06 0x09 0x06 0x0c 0x06 0x02 0x06 0x02 0x13 0x2b 0x4e 0x03 >;
				phandle = < 0x101 >;
			};

			iommu@60a0c000 {
				compatible = "sprd,iommuex-dcam";
				reg = < 0x60a0c000 0x60 >;
				sprd,frc-reg = < 0x60a03010 >;
				sprd,iova-base = < 0x40000000 >;
				sprd,iova-size = < 0x20000000 >;
				reg_name = "mmu_reg";
				status = "okay";
				#iommu-cells = < 0x00 >;
				phandle = < 0x4c >;
			};

			isp@60b00000 {
				compatible = "sprd,isp";
				reg = < 0x60b00000 0x100000 >;
				interrupts = < 0x00 0x2c 0x04 0x00 0x7d 0x04 >;
				interrupts_name = "ch0\0ch1";
				syscons = < 0x4a 0x04 0x80 >;
				syscon-names = "reset";
				sprd,cam-ahb-syscon = < 0x4a >;
				sprd,isp-count = < 0x01 >;
				iommus = < 0x4f >;
				status = "okay";
				clock-names = "isp_eb\0isp_axi_eb\0isp_clk\0isp_clk_128m\0isp_clk_256m\0isp_clk_307m2\0isp_clk_384m\0isp_clk_468m\0isp_clk_parent";
				clocks = < 0x4d 0x02 0x4d 0x07 0x13 0x2d 0x06 0x0a 0x06 0x09 0x06 0x0c 0x06 0x02 0x06 0x19 0x06 0x19 >;
				phandle = < 0x4b >;
			};

			iommu@60bffc00 {
				compatible = "sprd,iommuex-isp";
				reg = < 0x60bffc00 0x400 >;
				sprd,iova-base = < 0x50000000 >;
				sprd,iova-size = < 0x20000000 >;
				reg_name = "mmu_reg";
				status = "okay";
				#iommu-cells = < 0x00 >;
				phandle = < 0x4f >;
			};

			csi@60c00000 {
				compatible = "sprd,csi-controller";
				reg = < 0x60c00000 0x1000 >;
				interrupts = < 0x00 0x28 0x04 0x00 0x29 0x04 >;
				sprd,aon-apb-syscon = < 0x02 >;
				sprd,cam-ahb-syscon = < 0x4a >;
				sprd,anlg_phy_g1_controller = < 0x03 >;
				sprd,csi-id = < 0x00 >;
				sprd,dcam-id = < 0x00 >;
				sprd,ip-version = < 0x200 >;
				status = "okay";
				clock-names = "clk_mipi_csi_gate_eb\0clk_csi_eb\0mipi_csi_src_eb\0clk_gate_eb";
				clocks = < 0x4d 0x08 0x4d 0x03 0x50 0x00 0x4d 0x00 >;
				phandle = < 0x102 >;
			};

			csi@60d00000 {
				compatible = "sprd,csi-controller";
				reg = < 0x60d00000 0x1000 >;
				interrupts = < 0x00 0x47 0x04 0x00 0x48 0x04 >;
				sprd,aon-apb-syscon = < 0x02 >;
				sprd,cam-ahb-syscon = < 0x4a >;
				sprd,anlg_phy_g1_controller = < 0x03 >;
				sprd,csi-id = < 0x01 >;
				sprd,dcam-id = < 0x01 >;
				sprd,ip-version = < 0x200 >;
				status = "okay";
				clock-names = "clk_mipi_csi_gate_eb\0clk_csi_eb\0mipi_csi_src_eb\0clk_gate_eb";
				clocks = < 0x4d 0x09 0x4d 0x04 0x50 0x01 0x4d 0x00 >;
				phandle = < 0x103 >;
			};

			csi@60e00000 {
				compatible = "sprd,csi-controller";
				reg = < 0x60e00000 0x1000 >;
				interrupts = < 0x00 0x9c 0x04 0x00 0x9d 0x04 >;
				sprd,aon-apb-syscon = < 0x02 >;
				sprd,cam-ahb-syscon = < 0x4a >;
				sprd,anlg_phy_g1_controller = < 0x03 >;
				sprd,csi-id = < 0x02 >;
				sprd,dcam-id = < 0x02 >;
				sprd,ip-version = < 0x200 >;
				status = "okay";
				clock-names = "clk_mipi_csi_gate_eb\0clk_csi_eb\0mipi_csi_src_eb\0clk_gate_eb";
				clocks = < 0x4d 0x0a 0x4d 0x05 0x50 0x02 0x4d 0x00 >;
				phandle = < 0x104 >;
			};

			cpp@62400000 {
				compatible = "sprd,cpp";
				reg = < 0x62400000 0x1000 >;
				interrupts = < 0x00 0x7e 0x04 >;
				syscons = < 0x41 0x04 0x3c0 0x41 0x04 0x80 0x41 0x04 0x100 0x41 0x04 0x200 >;
				syscon-names = "cpp_rst\0path0_rst\0path1_rst\0dma_rst";
				iommus = < 0x51 >;
				status = "okay";
				clock-names = "cpp_eb\0cpp_clk\0cpp_clk_parent\0clk_mm_vsp_eb\0clk_mm_vsp_emc\0clk_mm_vsp_emc_parent";
				clocks = < 0x43 0x03 0x13 0x2f 0x06 0x0c 0x05 0x2c 0x13 0x33 0x06 0x19 >;
				phandle = < 0x105 >;
			};

			iommu@62400200 {
				compatible = "sprd,iommuex-cpp";
				reg = < 0x62400200 0x60 >;
				sprd,iova-base = < 0x60000000 >;
				sprd,iova-size = < 0x8000000 >;
				reg_name = "mmu_reg";
				status = "okay";
				#iommu-cells = < 0x00 >;
				phandle = < 0x51 >;
			};
		};

		pub {
			compatible = "simple-bus";
			#address-cells = < 0x02 >;
			#size-cells = < 0x02 >;
			ranges;

			dmc-controller@30000000 {
				compatible = "sprd,sharkl3-dmc";
				reg = < 0x00 0x30000000 0x00 0x1000 >;
				phandle = < 0x106 >;
			};

			ptm@30010000 {
				compatible = "sprd,sharkl3-ptm";
				reg = < 0x00 0x30010000 0x00 0x10000 0x00 0x10001000 0x00 0x1000 0x00 0x10003000 0x00 0x1000 0x00 0x10004000 0x00 0x1000 >;
				interrupts = < 0x00 0x56 0x04 >;
				clock-names = "clk_cs\0cs_src";
				clocks = < 0x13 0x18 0x06 0x0f >;
				sprd,funnel-port = < 0x02 >;
				sprd,ddr-chn = < 0x08 >;
				sprd,chn-name = "MM\0GPU\0DPU\0CPU\0AP/PUBCP\0WTLCP\0WCN/AON/ETR\0VSP";
				phandle = < 0x107 >;
			};

			dmc-mpu@300e0000 {
				compatible = "sprd,sharkl3-dmc-mpu";
				reg = < 0x00 0x300e0000 0x00 0x10000 >;
				interrupts = < 0x00 0x3d 0x04 >;
				syscon-names = "irq_clr\0irq_en";
				syscons = < 0x52 0x40 0x02 0x52 0x40 0x01 >;
				sprd,channel-num = < 0x08 >;
				sprd,mpu-num = < 0x10 >;
				sprd,channel-names = "MM\0GPU\0DPU\0CPU\0AP/PUBCP\0WTLCP\0AON/WCN/ETR\0VSP\0SHARED0\0SHARED1\0SHARED2\0SHARED3\0SHARED4\0SHARED5\0SHARED6\0SHARED7";
				sprd,ranges = < 0x00 0x00 0x00 0x00 0x00 0x00 0x00 0x00 0x00 0x00 0x00 0x00 0x00 0x00 0x00 0x00 0x00 0x00 0x00 0x00 0x00 0x00 0x00 0x00 0x00 0x00 0x00 0x00 0x00 0x00 0x00 0x00 0x00 0x00 0x00 0x00 0x00 0x00 0x00 0x00 0x00 0x00 0x00 0x00 0x00 0x00 0x00 0x00 0x00 0x00 0x00 0x00 0x00 0x00 0x00 0x00 0x00 0x00 0x00 0x00 0x00 0x00 0x00 0x00 >;
				sprd,chn-config = < 0x00 0x01 0x01 0x00 0x01 0x01 0x00 0x01 0x01 0x00 0x01 0x01 0x00 0x01 0x01 0x00 0x01 0x01 0x00 0x01 0x01 0x00 0x01 0x01 0x00 0x01 0x01 0x00 0x01 0x01 0x00 0x01 0x01 0x00 0x01 0x01 0x00 0x01 0x01 0x00 0x01 0x01 0x00 0x01 0x01 0x00 0x01 0x01 >;
				sprd,id-config = < 0x00 0x00 0xffff 0x00 0x00 0xffff 0x00 0x00 0xffff 0x00 0x00 0xffff 0x00 0x00 0xffff 0x00 0x00 0xffff 0x00 0x00 0xffff 0x00 0x00 0xffff 0x00 0x00 0xffff 0x00 0x00 0xffff 0x00 0x00 0xffff 0x00 0x00 0xffff 0x00 0x00 0xffff 0x00 0x00 0xffff 0x00 0x00 0xffff 0x00 0x00 0xffff >;
				sprd,port-map = < 0x00 0x01 0x02 0x03 0x04 0x05 0x06 0x07 0x00 0x00 0x00 0x00 0x00 0x00 0x00 0x00 >;
				sprd,ddr-offset = < 0x80000000 >;
				status = "disabled";
				phandle = < 0x108 >;
			};
		};

		pmu-gate {
			compatible = "sprd,sc9863a-pmu-gate";
			sprd,syscon = < 0x07 >;
			clocks = < 0x0a >;
			#clock-cells = < 0x01 >;
			phandle = < 0x53 >;
		};

		pll {
			compatible = "sprd,sc9863a-pll";
			sprd,syscon = < 0x04 >;
			clocks = < 0x53 0x00 >;
			#clock-cells = < 0x01 >;
			phandle = < 0x06 >;
		};

		mpll {
			compatible = "sprd,sc9863a-mpll";
			sprd,syscon = < 0x0f >;
			clocks = < 0x53 0x00 >;
			#clock-cells = < 0x01 >;
			phandle = < 0x8e >;
		};

		rpll {
			compatible = "sprd,sc9863a-rpll";
			sprd,syscon = < 0x54 >;
			clocks = < 0x53 0x00 >;
			#clock-cells = < 0x01 >;
			phandle = < 0x14 >;
		};

		dpll {
			compatible = "sprd,sc9863a-dpll";
			sprd,syscon = < 0x18 >;
			clocks = < 0x53 0x00 >;
			#clock-cells = < 0x01 >;
			phandle = < 0x4e >;
		};

		clock-controller@21500000 {
			compatible = "sprd,sc9863a-ap-clk";
			reg = < 0x00 0x21500000 0x00 0x1000 >;
			clocks = < 0x2e 0x0a 0x06 0x00 0x14 0x00 >;
			#clock-cells = < 0x01 >;
			phandle = < 0x09 >;
		};

		clock-controller@402d0000 {
			compatible = "sprd,sc9863a-aon-clk";
			reg = < 0x00 0x402d0000 0x00 0x1000 >;
			clocks = < 0x0a 0x06 0x00 0x14 0x00 0x4e 0x00 >;
			#clock-cells = < 0x01 >;
			phandle = < 0x13 >;
		};

		apahb-gate {
			compatible = "sprd,sc9863a-apahb-gate";
			sprd,syscon = < 0x0e >;
			clocks = < 0x13 0x1d >;
			#clock-cells = < 0x01 >;
			phandle = < 0x0c >;
		};

		aonapb-gate {
			compatible = "sprd,sc9863a-aonapb-gate";
			sprd,syscon = < 0x02 >;
			clocks = < 0x13 0x09 >;
			#clock-cells = < 0x01 >;
			phandle = < 0x05 >;
		};

		clock-controller@60900000 {
			compatible = "sprd,sc9863a-mm-clk";
			reg = < 0x00 0x60900000 0x00 0x1000 >;
			clocks = < 0x13 0x2a >;
			#clock-cells = < 0x01 >;
			phandle = < 0x50 >;
		};

		mm-gate {
			compatible = "sprd,sc9863a-mm-gate";
			sprd,syscon = < 0x4a >;
			syscons = < 0x02 0x00 0x2000000 0x07 0x1c 0x2000000 >;
			syscon-names = "enable\0power";
			clocks = < 0x13 0x2a >;
			#clock-cells = < 0x01 >;
			phandle = < 0x4d >;
		};

		vspahb-gate {
			compatible = "sprd,sc9863a-vspahb-gate";
			sprd,syscon = < 0x41 >;
			syscons = < 0x02 0x04 0x4000 0x07 0x30 0x2000000 >;
			syscon-names = "enable\0power";
			clocks = < 0x13 0x2a >;
			#clock-cells = < 0x01 >;
			phandle = < 0x43 >;
		};

		apapb-gate {
			compatible = "sprd,sc9863a-apapb-gate";
			sprd,syscon = < 0x0b >;
			clocks = < 0x0a >;
			#clock-cells = < 0x01 >;
			phandle = < 0x08 >;
		};

		funnel@10001000 {
			compatible = "arm,coresight-funnel\0arm,primecell";
			reg = < 0x00 0x10001000 0x00 0x1000 >;
			clocks = < 0x0a >;
			clock-names = "apb_pclk";

			ports {
				#address-cells = < 0x01 >;
				#size-cells = < 0x00 >;

				port@0 {
					reg = < 0x00 >;

					endpoint {
						remote-endpoint = < 0x55 >;
						phandle = < 0x57 >;
					};
				};

				port@1 {
					reg = < 0x00 >;

					endpoint {
						slave-mode;
						remote-endpoint = < 0x56 >;
						phandle = < 0x61 >;
					};
				};
			};
		};

		etb@10003000 {
			compatible = "arm,coresight-tmc\0arm,primecell";
			reg = < 0x00 0x10003000 0x00 0x1000 >;
			clocks = < 0x0a >;
			clock-names = "apb_pclk";
			phandle = < 0x81 >;

			port {

				endpoint {
					slave-mode;
					remote-endpoint = < 0x57 >;
					phandle = < 0x55 >;
				};
			};
		};

		funnel@12001000 {
			compatible = "arm,coresight-funnel\0arm,primecell";
			reg = < 0x00 0x12001000 0x00 0x1000 >;
			clocks = < 0x0a >;
			clock-names = "apb_pclk";

			ports {
				#address-cells = < 0x01 >;
				#size-cells = < 0x00 >;

				port@0 {
					reg = < 0x00 >;

					endpoint {
						remote-endpoint = < 0x58 >;
						phandle = < 0x5e >;
					};
				};

				port@1 {
					reg = < 0x00 >;

					endpoint {
						slave-mode;
						remote-endpoint = < 0x59 >;
						phandle = < 0x6a >;
					};
				};

				port@2 {
					reg = < 0x01 >;

					endpoint {
						slave-mode;
						remote-endpoint = < 0x5a >;
						phandle = < 0x6c >;
					};
				};

				port@3 {
					reg = < 0x02 >;

					endpoint {
						slave-mode;
						remote-endpoint = < 0x5b >;
						phandle = < 0x6e >;
					};
				};

				port@4 {
					reg = < 0x03 >;

					endpoint {
						slave-mode;
						remote-endpoint = < 0x5c >;
						phandle = < 0x70 >;
					};
				};
			};
		};

		etf@12002000 {
			compatible = "arm,coresight-tmc\0arm,primecell";
			reg = < 0x00 0x12002000 0x00 0x1000 >;
			clocks = < 0x0a >;
			clock-names = "apb_pclk";

			port@0 {

				endpoint {
					remote-endpoint = < 0x5d >;
					phandle = < 0x62 >;
				};
			};

			port@1 {

				endpoint {
					slave-mode;
					remote-endpoint = < 0x5e >;
					phandle = < 0x58 >;
				};
			};
		};

		etf@12003000 {
			compatible = "arm,coresight-tmc\0arm,primecell";
			reg = < 0x00 0x12003000 0x00 0x1000 >;
			clocks = < 0x0a >;
			clock-names = "apb_pclk";

			port@0 {

				endpoint {
					remote-endpoint = < 0x5f >;
					phandle = < 0x63 >;
				};
			};

			port@1 {

				endpoint {
					slave-mode;
					remote-endpoint = < 0x60 >;
					phandle = < 0x64 >;
				};
			};
		};

		funnel@12004000 {
			compatible = "arm,coresight-funnel\0arm,primecell";
			reg = < 0x00 0x12004000 0x00 0x1000 >;
			clocks = < 0x0a >;
			clock-names = "apb_pclk";

			ports {
				#address-cells = < 0x01 >;
				#size-cells = < 0x00 >;

				port@0 {
					reg = < 0x00 >;

					endpoint {
						remote-endpoint = < 0x61 >;
						phandle = < 0x56 >;
					};
				};

				port@1 {
					reg = < 0x00 >;

					endpoint {
						slave-mode;
						remote-endpoint = < 0x62 >;
						phandle = < 0x5d >;
					};
				};

				port@2 {
					reg = < 0x01 >;

					endpoint {
						slave-mode;
						remote-endpoint = < 0x63 >;
						phandle = < 0x5f >;
					};
				};
			};
		};

		funnel@12005000 {
			compatible = "arm,coresight-funnel\0arm,primecell";
			reg = < 0x00 0x12005000 0x00 0x1000 >;
			clocks = < 0x0a >;
			clock-names = "apb_pclk";

			ports {
				#address-cells = < 0x01 >;
				#size-cells = < 0x00 >;

				port@0 {
					reg = < 0x00 >;

					endpoint {
						remote-endpoint = < 0x64 >;
						phandle = < 0x60 >;
					};
				};

				port@1 {
					reg = < 0x00 >;

					endpoint {
						slave-mode;
						remote-endpoint = < 0x65 >;
						phandle = < 0x72 >;
					};
				};

				port@2 {
					reg = < 0x01 >;

					endpoint {
						slave-mode;
						remote-endpoint = < 0x66 >;
						phandle = < 0x74 >;
					};
				};

				port@3 {
					reg = < 0x02 >;

					endpoint {
						slave-mode;
						remote-endpoint = < 0x67 >;
						phandle = < 0x76 >;
					};
				};

				port@4 {
					reg = < 0x03 >;

					endpoint {
						slave-mode;
						remote-endpoint = < 0x68 >;
						phandle = < 0x78 >;
					};
				};
			};
		};

		etm@13040000 {
			compatible = "arm,coresight-etm4x\0arm,primecell";
			reg = < 0x00 0x13040000 0x00 0x1000 >;
			cpu = < 0x69 >;
			clocks = < 0x0a >;
			clock-names = "apb_pclk";
			phandle = < 0x79 >;

			port {

				endpoint {
					remote-endpoint = < 0x6a >;
					phandle = < 0x59 >;
				};
			};
		};

		etm@13140000 {
			compatible = "arm,coresight-etm4x\0arm,primecell";
			reg = < 0x00 0x13140000 0x00 0x1000 >;
			cpu = < 0x6b >;
			clocks = < 0x0a >;
			clock-names = "apb_pclk";
			phandle = < 0x7a >;

			port {

				endpoint {
					remote-endpoint = < 0x6c >;
					phandle = < 0x5a >;
				};
			};
		};

		etm@13240000 {
			compatible = "arm,coresight-etm4x\0arm,primecell";
			reg = < 0x00 0x13240000 0x00 0x1000 >;
			cpu = < 0x6d >;
			clocks = < 0x0a >;
			clock-names = "apb_pclk";
			phandle = < 0x7b >;

			port {

				endpoint {
					remote-endpoint = < 0x6e >;
					phandle = < 0x5b >;
				};
			};
		};

		etm@13340000 {
			compatible = "arm,coresight-etm4x\0arm,primecell";
			reg = < 0x00 0x13340000 0x00 0x1000 >;
			cpu = < 0x6f >;
			clocks = < 0x0a >;
			clock-names = "apb_pclk";
			phandle = < 0x7c >;

			port {

				endpoint {
					remote-endpoint = < 0x70 >;
					phandle = < 0x5c >;
				};
			};
		};

		etm@13440000 {
			compatible = "arm,coresight-etm4x\0arm,primecell";
			reg = < 0x00 0x13440000 0x00 0x1000 >;
			cpu = < 0x71 >;
			clocks = < 0x0a >;
			clock-names = "apb_pclk";
			phandle = < 0x7d >;

			port {

				endpoint {
					remote-endpoint = < 0x72 >;
					phandle = < 0x65 >;
				};
			};
		};

		etm@13540000 {
			compatible = "arm,coresight-etm4x\0arm,primecell";
			reg = < 0x00 0x13540000 0x00 0x1000 >;
			cpu = < 0x73 >;
			clocks = < 0x0a >;
			clock-names = "apb_pclk";
			phandle = < 0x7e >;

			port {

				endpoint {
					remote-endpoint = < 0x74 >;
					phandle = < 0x66 >;
				};
			};
		};

		etm@13640000 {
			compatible = "arm,coresight-etm4x\0arm,primecell";
			reg = < 0x00 0x13640000 0x00 0x1000 >;
			cpu = < 0x75 >;
			clocks = < 0x0a >;
			clock-names = "apb_pclk";
			phandle = < 0x7f >;

			port {

				endpoint {
					remote-endpoint = < 0x76 >;
					phandle = < 0x67 >;
				};
			};
		};

		etm@13740000 {
			compatible = "arm,coresight-etm4x\0arm,primecell";
			reg = < 0x00 0x13740000 0x00 0x1000 >;
			cpu = < 0x77 >;
			clocks = < 0x0a >;
			clock-names = "apb_pclk";
			phandle = < 0x80 >;

			port {

				endpoint {
					remote-endpoint = < 0x78 >;
					phandle = < 0x68 >;
				};
			};
		};

		apetb {
			compatible = "sprd,apetb";
			apetb-source = < 0x79 0x7a 0x7b 0x7c 0x7d 0x7e 0x7f 0x80 >;
			apetb-sink = < 0x81 >;
			phandle = < 0x109 >;
		};
	};

	ext-26m {
		compatible = "fixed-clock";
		#clock-cells = < 0x00 >;
		clock-frequency = < 0x18cba80 >;
		clock-output-names = "ext-26m";
		phandle = < 0x0a >;
	};

	ext-13m {
		compatible = "fixed-clock";
		#clock-cells = < 0x00 >;
		clock-frequency = < 0xc65d40 >;
		clock-output-names = "ext_13m";
		phandle = < 0x10a >;
	};

	ext-6m5 {
		compatible = "fixed-clock";
		#clock-cells = < 0x00 >;
		clock-frequency = < 0x632ea0 >;
		clock-output-names = "ext_6m5";
		phandle = < 0x10b >;
	};

	ext-4m3 {
		compatible = "fixed-clock";
		#clock-cells = < 0x00 >;
		clock-frequency = < 0x419ce0 >;
		clock-output-names = "ext_4m3";
		phandle = < 0x10c >;
	};

	ext-4m {
		compatible = "fixed-clock";
		#clock-cells = < 0x00 >;
		clock-frequency = < 0x3d0900 >;
		clock-output-names = "ext_4m";
		phandle = < 0x10d >;
	};

	ext-250k {
		compatible = "fixed-clock";
		#clock-cells = < 0x00 >;
		clock-frequency = < 0x3d090 >;
		clock-output-names = "ext_250k";
		phandle = < 0x10e >;
	};

	ext-32k {
		compatible = "fixed-clock";
		#clock-cells = < 0x00 >;
		clock-frequency = < 0x8000 >;
		clock-output-names = "ext_32k";
		phandle = < 0x2e >;
	};

	ext-1k {
		compatible = "fixed-clock";
		#clock-cells = < 0x00 >;
		clock-frequency = < 0x400 >;
		clock-output-names = "ext_1k";
		phandle = < 0x2d >;
	};

	ext-1m {
		compatible = "fixed-clock";
		#clock-cells = < 0x00 >;
		clock-frequency = < 0xf4240 >;
		clock-output-names = "ext_1m";
		phandle = < 0x10f >;
	};

	ext-2m {
		compatible = "fixed-clock";
		#clock-cells = < 0x00 >;
		clock-frequency = < 0x1e8480 >;
		clock-output-names = "ext_2m";
		phandle = < 0x110 >;
	};

	ext-rc0-4m {
		compatible = "fixed-clock";
		#clock-cells = < 0x00 >;
		clock-frequency = < 0x3d0900 >;
		clock-output-names = "ext_rc0_4m";
		phandle = < 0x111 >;
	};

	clk-pad {
		compatible = "fixed-clock";
		#clock-cells = < 0x00 >;
		clock-frequency = < 0x3d09000 >;
		clock-output-names = "clk_pad";
		phandle = < 0x112 >;
	};

	rco-100m {
		compatible = "fixed-clock";
		#clock-cells = < 0x00 >;
		clock-frequency = < 0x5f5e100 >;
		clock-output-names = "rco-100m";
		phandle = < 0x113 >;
	};

	sprd-pcm-audio {
		compatible = "sprd,sharkl3-pcm-platform";
		#sound-dai-cells = < 0x00 >;
		dmas = < 0x82 0x01 0x82 0x02 0x82 0x03 0x82 0x04 0x82 0x05 0x82 0x06 0x82 0x07 0x82 0x08 0x82 0x05 0x82 0x06 >;
		dma-names = "da01-l\0da01-r\0da23-l\0da23-r\0normal-2stage-p\0normal-2stage-c\0deep-2stage-p\0ad23-2stage-c\0ad01-l\0ad01-r";
		sprd,dma-2stage-usecase = < 0x02 >;
		sprd,node-count-2stage-level-1 = < 0x01 >;
		sprd,syscon-pmu-apb = < 0x07 >;
		sprd,dma-2stage-level-1-int-source = < 0x01 >;
		phandle = < 0xa9 >;
	};

	vaudio {
		compatible = "sprd,vaudio";
		#sound-dai-cells = < 0x01 >;
		clock-names = "tuned_26m";
		clocks = < 0x14 0x00 >;
		phandle = < 0xac >;
	};

	sprd-pcm-iis {
		compatible = "sprd,sharkl3-pcm-platform";
		#sound-dai-cells = < 0x00 >;
		dmas = < 0x83 0x05 0x83 0x06 >;
		dma-names = "iis0_tx\0iis0_rx";
		sprd,dma-2stage-usecase = < 0x02 >;
		sprd,node-count-2stage-level-1 = < 0x01 >;
		sprd,syscon-pmu-apb = < 0x07 >;
		sprd,dma-2stage-level-1-int-source = < 0x01 >;
		phandle = < 0xad >;
	};

	saudio_lte {
		compatible = "sprd,saudio";
		sprd,saudio-dst-id = < 0x05 >;
		sprd,ctrl_channel = < 0x0a >;
		sprd,playback_channel = < 0x0b 0x83 0x84 >;
		sprd,capture_channel = < 0x0c >;
		sprd,monitor_channel = < 0x0d >;
		sprd,device = < 0x03 >;
		sprd,saudio-names = "saudiolte";
	};

	saudio_voip {
		compatible = "sprd,saudio";
		sprd,saudio-dst-id = < 0x05 >;
		sprd,ctrl_channel = < 0x0e >;
		sprd,playback_channel = < 0x0f 0x97 >;
		sprd,capture_channel = < 0x10 >;
		sprd,monitor_channel = < 0x11 >;
		sprd,device = < 0x02 >;
		sprd,saudio-names = "saudiovoip";
	};

	audio-mem-mgr {
		compatible = "sprd,sharkl3-audio-mem";
		sprd,iram_phy_addr = < 0x2000 0xb000 >;
		sprd,iram_normal = < 0x2000 0x00 >;
		sprd,iram_deepbuf = < 0x2000 0xa000 >;
		sprd,iram_4arm7 = < 0xc000 0x1000 >;
	};

	apipe-pcm {
		compatible = "sprd,apipe";
	};

	apipe-cmd-in {
		compatible = "sprd,apipe";
	};

	apipe-cmd-out {
		compatible = "sprd,apipe";
	};

	cpus {
		#address-cells = < 0x02 >;
		#size-cells = < 0x00 >;

		cpu-map {

			cluster0 {

				core0 {
					cpu = < 0x69 >;
				};

				core1 {
					cpu = < 0x6b >;
				};

				core2 {
					cpu = < 0x6d >;
				};

				core3 {
					cpu = < 0x6f >;
				};
			};

			cluster1 {

				core0 {
					cpu = < 0x71 >;
				};

				core1 {
					cpu = < 0x73 >;
				};

				core2 {
					cpu = < 0x75 >;
				};

				core3 {
					cpu = < 0x77 >;
				};
			};
		};

		cpu@0 {
			device_type = "cpu";
			compatible = "arm,cortex-a55\0arm,armv8";
			reg = < 0x00 0x00 >;
			enable-method = "psci";
			cpu-supply = < 0x84 >;
			cpufreq-data-v1 = < 0x85 >;
			cpu-idle-states = < 0x86 >;
			sched-energy-costs = < 0x87 0x88 >;
			capacity-dmips-mhz = < 0x400 >;
			sugov_slack_timer;
			phandle = < 0x69 >;
		};

		cpu@100 {
			device_type = "cpu";
			compatible = "arm,cortex-a55\0arm,armv8";
			reg = < 0x00 0x100 >;
			enable-method = "psci";
			cpu-supply = < 0x84 >;
			cpufreq-data-v1 = < 0x85 >;
			cpu-idle-states = < 0x86 >;
			sched-energy-costs = < 0x87 0x88 >;
			capacity-dmips-mhz = < 0x400 >;
			phandle = < 0x6b >;
		};

		cpu@200 {
			device_type = "cpu";
			compatible = "arm,cortex-a55\0arm,armv8";
			reg = < 0x00 0x200 >;
			enable-method = "psci";
			cpu-supply = < 0x84 >;
			cpufreq-data-v1 = < 0x85 >;
			cpu-idle-states = < 0x86 >;
			sched-energy-costs = < 0x87 0x88 >;
			capacity-dmips-mhz = < 0x400 >;
			phandle = < 0x6d >;
		};

		cpu@300 {
			device_type = "cpu";
			compatible = "arm,cortex-a55\0arm,armv8";
			reg = < 0x00 0x300 >;
			enable-method = "psci";
			cpu-supply = < 0x84 >;
			cpufreq-data-v1 = < 0x85 >;
			cpu-idle-states = < 0x86 >;
			sched-energy-costs = < 0x87 0x88 >;
			capacity-dmips-mhz = < 0x400 >;
			phandle = < 0x6f >;
		};

		cpu@400 {
			device_type = "cpu";
			compatible = "arm,cortex-a55\0arm,armv8";
			reg = < 0x00 0x400 >;
			enable-method = "psci";
			cpu-supply = < 0x89 >;
			cpufreq-data-v1 = < 0x8a >;
			cpu-idle-states = < 0x86 >;
			sched-energy-costs = < 0x8b 0x8c >;
			capacity-dmips-mhz = < 0x400 >;
			phandle = < 0x71 >;
		};

		cpu@500 {
			device_type = "cpu";
			compatible = "arm,cortex-a55\0arm,armv8";
			reg = < 0x00 0x500 >;
			enable-method = "psci";
			cpu-supply = < 0x89 >;
			cpufreq-data-v1 = < 0x8a >;
			cpu-idle-states = < 0x86 >;
			sched-energy-costs = < 0x8b 0x8c >;
			capacity-dmips-mhz = < 0x400 >;
			phandle = < 0x73 >;
		};

		cpu@600 {
			device_type = "cpu";
			compatible = "arm,cortex-a55\0arm,armv8";
			reg = < 0x00 0x600 >;
			enable-method = "psci";
			cpu-supply = < 0x89 >;
			cpufreq-data-v1 = < 0x8a >;
			cpu-idle-states = < 0x86 >;
			sched-energy-costs = < 0x8b 0x8c >;
			capacity-dmips-mhz = < 0x400 >;
			phandle = < 0x75 >;
		};

		cpu@700 {
			device_type = "cpu";
			compatible = "arm,cortex-a55\0arm,armv8";
			reg = < 0x00 0x700 >;
			enable-method = "psci";
			cpu-supply = < 0x89 >;
			cpufreq-data-v1 = < 0x8a >;
			cpu-idle-states = < 0x86 >;
			sched-energy-costs = < 0x8b 0x8c >;
			capacity-dmips-mhz = < 0x400 >;
			phandle = < 0x77 >;
		};
	};

	energy-costs {

		core-cost0 {
			busy-cost-data = < 0x1ec 0x50 0x236 0x65 0x280 0x7d 0x2c0 0x97 0x300 0xb5 >;
			idle-cost-data = < 0x19 0x19 0x00 >;
			phandle = < 0x87 >;
		};

		core-cost1 {
			busy-cost-data = < 0x1ec 0x6e 0x2a0 0xa0 0x310 0xce 0x380 0x102 0x3c0 0x131 0x400 0x160 >;
			idle-cost-data = < 0x2c 0x2c 0x00 >;
			phandle = < 0x8b >;
		};

		cluster-cost0 {
			busy-cost-data = < 0x1ec 0x01 0x236 0x02 0x280 0x03 0x2c0 0x04 0x300 0x05 >;
			idle-cost-data = < 0x00 0x00 0x00 >;
			phandle = < 0x88 >;
		};

		cluster-cost1 {
			busy-cost-data = < 0x1ec 0x44 0x2a0 0x55 0x310 0x6a 0x380 0x82 0x3c0 0x99 0x400 0xb3 >;
			idle-cost-data = < 0x2a 0x2a 0x2a >;
			phandle = < 0x8c >;
		};
	};

	idle-states {
		entry-method = "arm,psci";

		core_pd {
			compatible = "arm,idle-state";
			entry-latency-us = < 0x3e8 >;
			exit-latency-us = < 0x1f4 >;
			min-residency-us = < 0x9c4 >;
			local-timer-stop;
			arm,psci-suspend-param = < 0x10000 >;
			phandle = < 0x86 >;
		};
	};

	cpufreq-clus0 {
		cpufreq-cluster-id = < 0x00 >;
		nvmem-cells = < 0x8d >;
		nvmem-cell-names = "dvfs_bin";
		sprd,cpufreq-temp-threshold = < 0x41 >;
		clocks = < 0x13 0x36 0x13 0x37 0x13 0x38 0x13 0x39 0x06 0x01 0x8e 0x00 >;
		clock-names = "core_clk\0core1_clk\0core2_clk\0core3_clk\0low_freq_clk_parent\0high_freq_clk_parent";
		clock-latency = < 0xc350 >;
		voltage-tolerance = < 0x190d >;
		volt-share-masters-bits = < 0x01 >;
		operating-points = < 0x124f80 0x111e53 0x10c8e0 0x106738 0xf4240 0xfb01d 0xd7d20 0xee098 0xbb800 0xe04de >;
		operating-points-1 = < 0x124f80 0x100590 0x10c8e0 0xf5aaa 0xf4240 0xea38f 0xd7d20 0xdc7d5 0xbb800 0xdbba0 >;
		operating-points-2 = < 0x124f80 0x10c8e0 0x10c8e0 0x101dfa 0xf4240 0xf66df 0xd7d20 0xe8b25 0xbb800 0xdbba0 >;
		operating-points-3 = < 0x124f80 0x118c30 0x10c8e0 0x10e14a 0xf4240 0x102a2f 0xd7d20 0xf4e75 0xbb800 0xe7ef0 >;
		operating-points-1-65 = < 0x124f80 0x105b03 0x10c8e0 0xfa3e8 0xf4240 0xeeccd 0xd7d20 0xe1d48 0xbb800 0xdbba0 >;
		operating-points-2-65 = < 0x124f80 0x111e53 0x10c8e0 0x106738 0xf4240 0xfb01d 0xd7d20 0xee098 0xbb800 0xe04de >;
		operating-points-3-65 = < 0x10c8e0 0x112a88 0xf4240 0x10736d 0xd7d20 0xfa3e8 0xbb800 0xec82e >;
		phandle = < 0x85 >;
	};

	cpufreq-clus1 {
		cpufreq-cluster-id = < 0x01 >;
		nvmem-cells = < 0x8f >;
		nvmem-cell-names = "dvfs_bin";
		sprd,cpufreq-temp-threshold = < 0x41 >;
		cpufreq-sub-clusters = < 0x90 >;
		clocks = < 0x13 0x3a 0x13 0x3b 0x13 0x3c 0x13 0x3d 0x06 0x01 0x8e 0x01 >;
		clock-names = "core_clk\0core1_clk\0core2_clk\0core3_clk\0low_freq_clk_parent\0high_freq_clk_parent";
		clock-latency = < 0xc350 >;
		voltage-tolerance = < 0x00 >;
		volt-share-masters-bits = < 0x0a >;
		freq-sync-slaves-bits = < 0x08 >;
		operating-points = < 0x186a00 0x111e53 0x16e360 0x108bd7 0x155cc0 0x100590 0x12b128 0xf0537 0x100590 0xe1113 0xbb800 0xdbba0 >;
		operating-points-1 = < 0x186a00 0x100590 0x16e360 0xf7f49 0x155cc0 0xeeccd 0x12b128 0xdf8a9 0x100590 0xdbba0 0xbb800 0xdbba0 >;
		operating-points-2 = < 0x186a00 0x10c8e0 0x16e360 0x104299 0x155cc0 0xfb01d 0x12b128 0xebbf9 0x100590 0xdc7d5 0xbb800 0xdbba0 >;
		operating-points-3 = < 0x186a00 0x118c30 0x16e360 0x1105e9 0x155cc0 0x10736d 0x12b128 0xf7f49 0x100590 0xe8b25 0xbb800 0xdbba0 >;
		operating-points-1-65 = < 0x186a00 0x105b03 0x16e360 0xfc887 0x155cc0 0xf4240 0x12b128 0xe41e7 0x100590 0xdbba0 0xbb800 0xdbba0 >;
		operating-points-2-65 = < 0x186a00 0x111e53 0x16e360 0x108bd7 0x155cc0 0x100590 0x12b128 0xf0537 0x100590 0xe1113 0xbb800 0xdbba0 >;
		operating-points-3-65 = < 0x16e360 0x114f27 0x155cc0 0x10c8e0 0x12b128 0xfc887 0x100590 0xed463 0xbb800 0xdbba0 >;
		phandle = < 0x8a >;
	};

	cpufreq-fcm {
		cpufreq-cluster-id = < 0x03 >;
		nvmem-cells = < 0x91 >;
		nvmem-cell-names = "dvfs_bin";
		sprd,cpufreq-temp-threshold = < 0x41 >;
		clocks = < 0x13 0x3e 0x06 0x01 0x8e 0x02 >;
		clock-names = "clk\0clk_low\0clk_high";
		clock-latency = < 0xc350 >;
		voltage-tolerance = < 0x00 >;
		volt-share-masters-bits = < 0x0a >;
		freq-sync-hosts-bits = < 0x02 >;
		operating-points = < 0x1312d0 0x111e53 0x11e220 0x108bd7 0x10b558 0x100590 0xea218 0xf0537 0xc92c0 0xe1113 0xbb800 0xdbba0 >;
		operating-points-1 = < 0x1312d0 0x100590 0x11e220 0xf7f49 0x10b558 0xeeccd 0xea218 0xdf8a9 0xc92c0 0xdbba0 0xbb800 0xdbba0 >;
		operating-points-2 = < 0x1312d0 0x10c8e0 0x11e220 0x104299 0x10b558 0xfb01d 0xea218 0xebbf9 0xc92c0 0xdc7d5 0xbb800 0xdbba0 >;
		operating-points-3 = < 0x1312d0 0x118c30 0x11e220 0x1105e9 0x10b558 0x10736d 0xea218 0xf7f49 0xc92c0 0xe8b25 0xbb800 0xe1d48 >;
		operating-points-1-65 = < 0x1312d0 0x105b03 0x11e220 0xfc887 0x10b558 0xf4240 0xea218 0xe41e7 0xc92c0 0xdbba0 0xbb800 0xdbba0 >;
		operating-points-2-65 = < 0x1312d0 0x111e53 0x11e220 0x108bd7 0x10b558 0x100590 0xea218 0xf0537 0xc92c0 0xe1113 0xbb800 0xe04de >;
		operating-points-3-65 = < 0x11e220 0x114f27 0x10b558 0x10c8e0 0xea218 0xfc887 0xc92c0 0xed463 0xbb800 0xec82e >;
		phandle = < 0x90 >;
	};

	interrupt-controller@14000000 {
		compatible = "arm,gic-v3";
		#interrupt-cells = < 0x03 >;
		#address-cells = < 0x02 >;
		#size-cells = < 0x02 >;
		ranges;
		redistributor-stride = < 0x00 0x20000 >;
		#redistributor-regions = < 0x01 >;
		interrupt-controller;
		reg = < 0x00 0x14000000 0x00 0x20000 0x00 0x14040000 0x00 0x100000 >;
		interrupts = < 0x01 0x09 0x04 >;
		phandle = < 0x01 >;

		v2m@0 {
			compatible = "arm,gic-v2m-frame";
			msi-controller;
			reg = < 0x00 0x00 0x00 0x1000 >;
			phandle = < 0x114 >;
		};
	};

	psci {
		compatible = "arm,psci-0.2";
		method = "smc";
	};

	power-debug {
		compatible = "sprd,power-debug-sharkl3";
		sprd,enable = < 0x01 >;
		sprd,scan-interval = < 0x1e >;
		sprd,sys-ap-ahb = < 0x0e >;
		sprd,sys-ap-apb = < 0x0b >;
		sprd,sys-pmu-apb = < 0x07 >;
		sprd,sys-aon-apb = < 0x02 >;
		sprd,sys-ap-intc = < 0x92 0x93 0x94 0x95 0x96 0x97 >;
		phandle = < 0x115 >;
	};

	timer {
		compatible = "arm,armv8-timer";
		interrupts = < 0x01 0x0d 0x04 0x01 0x0e 0x04 0x01 0x0b 0x04 0x01 0x0a 0x04 >;
		arm,no-tick-in-suspend;
	};

	pmu {
		compatible = "arm,armv8-pmuv3";
		interrupts = < 0x00 0x90 0x04 0x00 0x91 0x04 0x00 0x92 0x04 0x00 0x93 0x04 0x00 0x94 0x04 0x00 0x95 0x04 0x00 0x96 0x04 0x00 0x97 0x04 >;
	};

	sprd-gsp {
		compatible = "sprd,gsp-r6p0-sharkl3";
		core-cnt = < 0x01 >;
		io-cnt = < 0x07 >;
		cores = < 0x98 >;
		power-domains = < 0x3f >;
		phandle = < 0xb7 >;
	};

	cpwcn_btwf {
		compatible = "sprd,integrate_marlin";
		sprd,name = "wcn_btwf";
		sprd,syscon-ap-apb = < 0x02 >;
		sprd,syscon-ap-pmu = < 0x07 >;
		sprd,syscon-ap-pub-apb = < 0x99 >;
		sprd,syscon-anlg-wrap-wcn = < 0x9a >;
		sprd,syscon-wcn-reg = < 0x9b >;
		sprd,syscon-anlg-phy-g5 = < 0x54 >;
		sprd,ctrl-probe-num = < 0x02 >;
		sprd,ctrl-reg = < 0x2004 0x3198 0x2100 0x20cc 0x20b0 0x1008 >;
		sprd,ctrl-mask = < 0x3000000 0x7ff 0x3000000 0x80000 0x10400 0x80 >;
		sprd,ctrl-value = < 0x3000000 0x102 0x3000000 0x80000 0x10400 0x80 >;
		sprd,ctrl-rw-offset = < 0x2000 0x00 0x2000 0x2000 0x2000 0x1000 >;
		sprd,ctrl-us-delay = < 0x0a 0x0a 0x0a 0x0a 0x0a 0x0a >;
		sprd,ctrl-type = < 0x03 0x00 0x01 0x01 0x01 0x03 >;
		sprd,ctrl-shutdown-reg = < 0x2008 0x10b0 >;
		sprd,ctrl-shutdown-mask = < 0x80 0x400 >;
		sprd,ctrl-shutdown-value = < 0x80 0x400 >;
		sprd,ctrl-shutdown-rw-offset = < 0x2000 0x1000 >;
		sprd,ctrl-shutdown-us-delay = < 0x0a 0x0a >;
		sprd,ctrl-shutdown-type = < 0x03 0x01 >;
		reg = < 0x00 0x84000000 0x00 0x180000 >;
		sprd,file-name = "/dev/block/platform/soc/soc:ap-ahb/20600000.sdio/by-name/wcnmodem";
		sprd,file-length = < 0x178000 >;
		memory_region = < 0x9c >;
		vddwcn-supply = < 0x9d >;
		vddwifipa-supply = < 0x9e >;
		#address-cells = < 0x01 >;
		#size-cells = < 0x01 >;
		nvmem-cells = < 0x9f 0xa0 0xa1 0xa2 >;
		nvmem-cell-names = "wcn_efuse_blk0\0wcn_efuse_blk1\0wcn_efuse_blk2\0wcn_efuse_blk3";
		phandle = < 0x116 >;
	};

	cpwcn_gnss {
		compatible = "sprd,integrate_gnss";
		sprd,name = "wcn_gnss";
		sprd,syscon-ap-apb = < 0x02 >;
		sprd,syscon-ap-pmu = < 0x07 >;
		sprd,syscon-ap-pub-apb = < 0x99 >;
		sprd,syscon-anlg-wrap-wcn = < 0x9a >;
		sprd,syscon-wcn-reg = < 0x9b >;
		sprd,syscon-anlg-phy-g5 = < 0x54 >;
		sprd,ctrl-probe-num = < 0x02 >;
		sprd,ctrl-reg = < 0x1004 0x3198 0x2100 0x20cc 0x20b0 0x1008 >;
		sprd,ctrl-mask = < 0xffffff 0x7ff 0x3000000 0x80000 0x10800 0x40 >;
		sprd,ctrl-value = < 0x300000 0x102 0x3000000 0x80000 0x10800 0x40 >;
		sprd,ctrl-rw-offset = < 0x1000 0x00 0x2000 0x2000 0x2000 0x1000 >;
		sprd,ctrl-us-delay = < 0x0a 0x0a 0x0a 0x0a 0x0a 0x0a >;
		sprd,ctrl-type = < 0x03 0x00 0x01 0x01 0x01 0x03 >;
		sprd,ctrl-shutdown-reg = < 0x2008 0x10b0 >;
		sprd,ctrl-shutdown-mask = < 0x40 0x800 >;
		sprd,ctrl-shutdown-value = < 0x40 0x800 >;
		sprd,ctrl-shutdown-rw-offset = < 0x2000 0x1000 >;
		sprd,ctrl-shutdown-us-delay = < 0x0a 0x0a >;
		sprd,ctrl-shutdown-type = < 0x03 0x01 >;
		reg = < 0x00 0x84300000 0x00 0x100000 >;
		sprd,file-name = "/dev/block/platform/soc/soc:ap-ahb/20600000.sdio/by-name/gpsgl";
		sprd,file-name-ext = "/dev/block/platform/soc/soc:ap-ahb/20600000.sdio/by-name/gpsbd";
		sprd,file-length = < 0x100000 >;
		memory_region = < 0xa3 >;
		vddwcn-supply = < 0x9d >;
		#address-cells = < 0x01 >;
		#size-cells = < 0x01 >;
		nvmem-cells = < 0xa2 0xa0 0xa1 >;
		nvmem-cell-names = "gnss_efuse_blk0\0gnss_efuse_blk1\0gnss_efuse_blk2";
		phandle = < 0x117 >;
	};

	wcn_sipc {
		compatible = "sprd,sipc";

		sipc@84180000 {
			sprd,name = "sipc-wcn";
			sprd,dst = < 0x03 0x05 >;
			sprd,smem-info = < 0x84180000 0x180000 0x180000 >;
			phandle = < 0x118 >;
		};

		sipc@8441b000 {
			sprd,name = "sipc-gnss";
			sprd,dst = < 0x04 0x06 >;
			sprd,smem-info = < 0x8441b000 0x11b000 0x32000 >;
			phandle = < 0x119 >;
		};
	};

	wcn_spipe {
		compatible = "sprd,spipe";

		spipe_cpwcn {
			sprd,name = "spipe_wcn";
			sprd,dst = < 0x03 >;
			sprd,channel = < 0x04 >;
			sprd,ringnr = < 0x10 >;
			sprd,size-rxbuf = < 0x2400 >;
			sprd,size-txbuf = < 0x2400 >;
		};

		spipe_gnss {
			sprd,name = "sttygnss0";
			sprd,dst = < 0x04 >;
			sprd,channel = < 0x04 >;
			sprd,ringnr = < 0x01 >;
			sprd,size-rxbuf = < 0x19000 >;
			sprd,size-txbuf = < 0xc800 >;
		};
	};

	wcn_wifi_cmd {
		compatible = "sprd,swcnblk";
		sprd,name = "wcn_wifi_cmd";
		sprd,dst = < 0x03 >;
		sprd,channel = < 0x07 >;
		sprd,tx-blksize = < 0x800 >;
		sprd,tx-blknum = < 0x04 >;
		sprd,rx-blksize = < 0x800 >;
		sprd,rx-blknum = < 0x10 >;
	};

	wcn_wifi_data0 {
		compatible = "sprd,swcnblk";
		sprd,name = "wcn_wifi_data0";
		sprd,dst = < 0x03 >;
		sprd,channel = < 0x08 >;
		sprd,tx-blksize = < 0x680 >;
		sprd,tx-blknum = < 0x40 >;
		sprd,rx-blksize = < 0x680 >;
		sprd,rx-blknum = < 0x100 >;
	};

	wcn_wifi_data1 {
		compatible = "sprd,swcnblk";
		sprd,name = "wcn_wifi_data1";
		sprd,dst = < 0x03 >;
		sprd,channel = < 0x09 >;
		sprd,tx-blksize = < 0x680 >;
		sprd,tx-blknum = < 0x40 >;
		sprd,rx-blksize = < 0x00 >;
		sprd,rx-blknum = < 0x00 >;
	};

	wcn_bt {
		compatible = "sprd,wcn_internal_chip";
		sprd,name = "ttyBT";
		sprd,dst = < 0x03 >;
		sprd,channel = < 0x04 >;
		sprd,tx_bufid = < 0x0b >;
		sprd,rx_bufid = < 0x0a >;
	};

	wcn_fm {
		compatible = "sprd,wcn_internal_chip";
		sprd,name = "fm";
		sprd,dst = < 0x03 >;
		sprd,tx_channel = < 0x04 >;
		sprd,rx_channel = < 0x04 >;
		sprd,tx_bufid = < 0x0e >;
		sprd,rx_bufid = < 0x0d >;
	};

	gnss_common_ctl {
		compatible = "sprd,gnss_common_ctl";
		sprd,name = "gnss_common_ctl";
	};

	scproc-pubcp {
		compatible = "sprd,scproc_pubcp";
		#address-cells = < 0x02 >;
		#size-cells = < 0x02 >;
		ranges;

		scproc@800000 {
			sprd,name = "pmic";
			syscons = < 0x02 0xff 0x00 0x07 0xff 0x100000 0x07 0xb0 0x80 0x02 0xff 0x00 0x02 0xff 0x00 >;
			syscon-names = "shutdown\0deepsleep\0corereset\0sysreset\0getstatus";
			reg = < 0x00 0x800000 0x00 0x40000 >;
			sprd,aon_iram = < 0x2000 0x15800 >;
			#address-cells = < 0x01 >;
			#size-cells = < 0x01 >;
			ranges = < 0x00 0x00 0x800000 0x3b000 0x3b000 0x00 0x83b000 0x5000 >;
			phandle = < 0x11a >;

			pm-sys@0 {
				cproc,name = "pm_sys";
				reg = < 0x00 0x3b000 >;
			};

			cali_lib@3b000 {
				cproc,name = "cali_lib";
				reg = < 0x3b000 0x5000 >;
			};
		};

		scproc@f000 {
			sprd,decoup = "cproc-use-decoup";
			sprd,name = "cptl";
			syscons = < 0x07 0x48 0x2000000 0x07 0xcc 0x40000 0x02 0x284 0x400 0x07 0xb0 0x02 0x02 0xff 0x00 0x02 0x130 0x30000 >;
			syscon-names = "shutdown\0deepsleep\0corereset\0sysreset\0getstatus\0dspreset";
			reg = < 0x00 0xf000 0x00 0x1000 >;
			interrupts = < 0x00 0x53 0x00 >;
			phandle = < 0x11b >;
		};
	};

	sprd-sipc {
		compatible = "sprd,sipc";

		sipc@88d80000 {
			sprd,name = "sipc-lte";
			sprd,dst = < 0x05 0x02 >;
			sprd,smem-info = < 0x88d80000 0x88d80000 0x880000 >;
			phandle = < 0x11c >;
		};

		sipc@d000 {
			sprd,name = "sipc-pmsys";
			sprd,dst = < 0x06 0x01 0x07 >;
			sprd,smem-info = < 0xd000 0x2000b000 0x2000 >;
			phandle = < 0x11d >;
		};
	};

	sprd-spipe {
		compatible = "sprd,spipe";

		spipe@0 {
			sprd,name = "spipe_pm";
			sprd,dst = < 0x06 >;
			sprd,channel = < 0x04 >;
			sprd,ringnr = < 0x02 >;
			sprd,size-rxbuf = < 0xb00 >;
			sprd,size-txbuf = < 0x180 >;
		};

		spipe@1 {
			sprd,name = "slog_pm";
			sprd,dst = < 0x06 >;
			sprd,channel = < 0x05 >;
			sprd,ringnr = < 0x01 >;
			sprd,size-rxbuf = < 0x500 >;
			sprd,size-txbuf = < 0x00 >;
		};

		spipe@2 {
			sprd,name = "sctl_pm";
			sprd,dst = < 0x06 >;
			sprd,channel = < 0x06 >;
			sprd,ringnr = < 0x01 >;
			sprd,size-rxbuf = < 0x40 >;
			sprd,size-txbuf = < 0x20 >;
		};

		spipe@3 {
			sprd,name = "spipe_lte";
			sprd,dst = < 0x05 >;
			sprd,channel = < 0x04 >;
			sprd,ringnr = < 0x0f >;
			sprd,size-rxbuf = < 0x1000 >;
			sprd,size-txbuf = < 0x1000 >;
		};

		spipe@4 {
			sprd,name = "sdiag_lte";
			sprd,dst = < 0x05 >;
			sprd,channel = < 0x15 >;
			sprd,ringnr = < 0x01 >;
			sprd,size-rxbuf = < 0x20000 >;
			sprd,size-txbuf = < 0x8000 >;
		};

		spipe@5 {
			sprd,name = "stty_lte";
			sprd,dst = < 0x05 >;
			sprd,channel = < 0x06 >;
			sprd,ringnr = < 0x20 >;
			sprd,size-rxbuf = < 0x800 >;
			sprd,size-txbuf = < 0x800 >;
		};

		spipe@6 {
			sprd,name = "stime_pm";
			sprd,dst = < 0x06 >;
			sprd,channel = < 0x29 >;
			sprd,ringnr = < 0x01 >;
			sprd,size-rxbuf = < 0x40 >;
			sprd,size-txbuf = < 0x80 >;
		};

		spipe@7 {
			sprd,name = "stty_lte_ss";
			sprd,dst = < 0x05 >;
			sprd,channel = < 0x58 >;
			sprd,ringnr = < 0x04 >;
			sprd,size-rxbuf = < 0x4400 >;
			sprd,size-txbuf = < 0x4400 >;
		};
	};

	sprd-spool {
		compatible = "sprd,spool";
		sprd,name = "slog_lte";
		sprd,dst = < 0x05 >;
		sprd,channel = < 0x05 >;
		sprd,tx-blksize = < 0x00 >;
		sprd,tx-blknum = < 0x00 >;
		sprd,rx-blksize = < 0x10000 >;
		sprd,rx-blknum = < 0x04 >;
	};

	sprd-sipx {
		compatible = "sprd,sipx";
		sprd,name = "sipx_lte";
		sprd,dst = < 0x05 >;
		sprd,dl-pool = < 0x800 >;
		sprd,dl-ack-pool = < 0x40 >;
		sprd,ul-pool = < 0x800 >;
		sprd,ul-ack-pool = < 0x400 >;
	};

	seth@0 {
		compatible = "sprd,seth";
		sprd,dst = < 0x05 >;
		sprd,channel = < 0x07 >;
		sprd,blknum = < 0x100 >;
		phandle = < 0x11e >;
	};

	seth@1 {
		compatible = "sprd,seth";
		sprd,dst = < 0x05 >;
		sprd,channel = < 0x08 >;
		sprd,blknum = < 0x100 >;
		phandle = < 0x11f >;
	};

	seth@2 {
		compatible = "sprd,seth";
		sprd,dst = < 0x05 >;
		sprd,channel = < 0x09 >;
		sprd,blknum = < 0x100 >;
		phandle = < 0x120 >;
	};

	seth@3 {
		compatible = "sprd,seth";
		sprd,dst = < 0x05 >;
		sprd,channel = < 0x12 >;
		sprd,blknum = < 0x100 >;
		phandle = < 0x121 >;
	};

	seth@4 {
		compatible = "sprd,seth";
		sprd,dst = < 0x05 >;
		sprd,channel = < 0x13 >;
		sprd,blknum = < 0x100 >;
		phandle = < 0x122 >;
	};

	seth@5 {
		compatible = "sprd,seth";
		sprd,dst = < 0x05 >;
		sprd,channel = < 0x14 >;
		sprd,blknum = < 0x100 >;
		phandle = < 0x123 >;
	};

	seth@6 {
		compatible = "sprd,seth";
		sprd,dst = < 0x05 >;
		sprd,channel = < 0x18 >;
		sprd,blknum = < 0x100 >;
		phandle = < 0x124 >;
	};

	seth@7 {
		compatible = "sprd,seth";
		sprd,dst = < 0x05 >;
		sprd,channel = < 0x19 >;
		sprd,blknum = < 0x100 >;
		phandle = < 0x125 >;
	};

	seth@8 {
		compatible = "sprd,seth";
		sprd,dst = < 0x05 >;
		sprd,channel = < 0x1a >;
		sprd,blknum = < 0x100 >;
		phandle = < 0x126 >;
	};

	seth@9 {
		compatible = "sprd,seth";
		sprd,dst = < 0x05 >;
		sprd,channel = < 0x1b >;
		sprd,blknum = < 0x100 >;
		phandle = < 0x127 >;
	};

	seth@10 {
		compatible = "sprd,seth";
		sprd,dst = < 0x05 >;
		sprd,channel = < 0x1c >;
		sprd,blknum = < 0x100 >;
		phandle = < 0x128 >;
	};

	seth@11 {
		compatible = "sprd,seth";
		sprd,dst = < 0x05 >;
		sprd,channel = < 0x1d >;
		sprd,blknum = < 0x100 >;
		phandle = < 0x129 >;
	};

	seth@12 {
		compatible = "sprd,seth";
		sprd,dst = < 0x05 >;
		sprd,channel = < 0x1e >;
		sprd,blknum = < 0x100 >;
		phandle = < 0x12a >;
	};

	seth@13 {
		compatible = "sprd,seth";
		sprd,dst = < 0x05 >;
		sprd,channel = < 0x1f >;
		sprd,blknum = < 0x100 >;
		phandle = < 0x12b >;
	};

	time_sync {
		compatible = "sprd,time-sync";
	};

	sprd-headset {
		compatible = "sprd,headset";
		status = "okay";
		jack-type = < 0x00 >;
		io-channels = < 0x10 0x14 >;
		io-channel-names = "headmic_in_little";
		gpios = < 0x3b 0x03 0x00 0x3b 0x08 0x00 0x3b 0x0c 0x00 0x3b 0x05 0x00 0x3b 0x0d 0x00 >;
		gpio-trigger-levels = < 0x01 0x01 0x01 0x01 0x01 >;
		gpio-dbnc-intervals = < 0x0a 0x64 0x64 0x64 0x64 >;
		gpio-names = "button\0detect_l\0detect_h\0detect_mic\0detect_all";
		adc-threshold-3pole-detect = < 0xbee >;
		sprd,adc-gnd = < 0x150 >;
		sprd,stable-value = < 0x8af >;
		sprd,coefficient = < 0xe573c >;
		irq-threshold-button = < 0x09 >;
		nvmem-cells = < 0xa4 0xa5 0xa6 >;
		nvmem-cell-names = "protectbit\0auxadc\0headmic";
		sprd,spk-route-hp;
		phandle = < 0xa7 >;

		headset-button@0 {
			adc-min = < 0x00 >;
			adc-max = < 0x1ea >;
			code = < 0xe2 >;
		};

		headset-button@1 {
			adc-min = < 0x21c >;
			adc-max = < 0x3fc >;
			code = < 0x73 >;
		};

		headset-button@2 {
			adc-min = < 0x442 >;
			adc-max = < 0x960 >;
			code = < 0x72 >;
		};
	};

	sound@0 {
		compatible = "sprd,vbc-r1p0v3-codec-sc2721";
		status = "okay";
		sprd-audio-card,name = "sprdphone";
		sprd-audio-card,routing = "HPMIC Pin\0HP Mic Jack\0MIC Pin\0Mic Jack\0MIC2 Pin\0Aux Mic Jack\0HeadPhone Jack\0HP Pin\0Ext Spk\0HP Pin\0Ext Spk1\0HP Pin\0Ext Spk\0SPK Pin\0Ext Spk1\0SPK Pin\0Ext Ear\0EAR Pin\0Ext Ear\0SPK Pin\0Ext Ear\0HP Pin\0DMIC\0DMic Jack\0DMIC1\0DMic1 Jack\0Aud input\0AD Clk\0Aud input1\0AD Clk\0Aud input\0Digital ADCL Switch\0Aud input\0Digital ADCR Switch\0Aud input1\0Digital ADC1L Switch\0Aud input1\0Digital ADC1R Switch";
		sprd-audio-card,headset = < 0xa7 >;
		sprd-audio-card,fm-open-src = < 0x01 >;
		sprd-audio-card,fm-hw-rate = < 0x7d00 >;
		sprd-audio-card,codec-replace-adc-rate = < 0xbb80 >;
		sprd,spk-ext-pa-info = < 0x00 0x00 0x02 0x00 >;
		sprd,spk-ext-pa-gpio = < 0xa8 0x9c 0x00 >;
		sprd,spk-ext-pa-id-gpio = < 0xa8 0x5a 0x00 >;
		phandle = < 0x12c >;

		sprd-audio-card,dai-link@0 {

			plat {
				sound-dai = < 0xa9 >;
			};

			cpu {
				sound-dai = < 0xaa 0x00 >;
			};

			codec {
				sound-dai = < 0xab 0x00 >;
			};
		};

		sprd-audio-card,dai-link@1 {

			plat {
				sound-dai = < 0xa9 >;
			};

			cpu {
				sound-dai = < 0xac 0x00 >;
			};

			codec {
				sound-dai = < 0xab 0x01 >;
			};
		};

		sprd-audio-card,dai-link@2 {

			plat {
				sound-dai = < 0xa9 >;
			};

			cpu {
				sound-dai = < 0xaa 0x01 >;
			};

			codec {
				sound-dai = < 0xab 0x03 >;
			};
		};

		sprd-audio-card,dai-link@3 {

			plat {
				sound-dai = < 0xa9 >;
			};

			cpu {
				sound-dai = < 0xac 0x01 >;
			};

			codec {
				sound-dai = < 0xab 0x04 >;
			};
		};

		sprd-audio-card,dai-link@4 {
			ops = < 0x00 >;

			plat {
				sound-dai = < 0xa9 >;
			};

			cpu {
				sound-dai = < 0xaa 0x02 >;
			};

			codec {
				sound-dai = < 0xab 0x05 >;
			};
		};

		sprd-audio-card,dai-link@5 {

			plat {
				sound-dai = < 0xa9 >;
			};

			cpu {
				sound-dai = < 0xaa 0x03 >;
			};

			codec {
				sound-dai = < 0xab 0x06 >;
			};
		};
	};

	sound@1 {
		compatible = "sprd,i2s-null-codec";
		status = "okay";
		sprd-audio-card,name = "all-i2s";
		phandle = < 0x12d >;

		sprd-audio-card,dai-link@0 {

			plat {
				sound-dai = < 0xad >;
			};

			cpu {
				sound-dai = < 0xae >;
			};

			codec {
				sound-dai = < 0x00 0x00 >;
			};
		};
	};

	memory {
		device_type = "memory";
		reg = < 0x00 0x80000000 0x00 0x80000000 >;
		phandle = < 0x12e >;
	};

	firmware {

		android {
			compatible = "android,firmware";

			vbmeta {
				compatible = "android,vbmeta";
				parts = "vbmeta,socko,odmko,boot,dtbo,l_modem,pm_sys,l_ldsp,l_gdsp";
				phandle = < 0x12f >;
			};
		};
	};

	ion {
		compatible = "sprd,ion";
		#address-cells = < 0x01 >;
		#size-cells = < 0x00 >;
		phandle = < 0x130 >;
	};

	thermal-zones {
		phandle = < 0x131 >;

		cpu-thmzone {
			polling-delay-passive = < 0x64 >;
			polling-delay = < 0x3e8 >;
			sustainable-power = < 0xbb8 >;
			thermal-sensors = < 0xaf 0x00 >;
			phandle = < 0x132 >;

			trips {

				trip-point@0 {
					temperature = < 0x11170 >;
					hysteresis = < 0x3e8 >;
					type = "passive";
					phandle = < 0x133 >;
				};

				trip-point@1 {
					temperature = < 0x14c08 >;
					hysteresis = < 0x3e8 >;
					type = "passive";
					phandle = < 0xb0 >;
				};

				bia_crit {
					temperature = < 0x1adb0 >;
					hysteresis = < 0x7d0 >;
					type = "critical";
					phandle = < 0x134 >;
				};
			};

			cooling-maps {

				map0 {
					trip = < 0xb0 >;
					contribution = < 0x400 >;
					cooling-device = < 0xb1 0xffffffff 0xffffffff >;
				};

				map1 {
					trip = < 0xb0 >;
					contribution = < 0x2a2 >;
					cooling-device = < 0xb2 0xffffffff 0xffffffff >;
				};
			};
		};

		gpu-thmzone {
			polling-delay-passive = < 0x00 >;
			polling-delay = < 0x00 >;
			thermal-sensors = < 0xb3 0x00 >;
			phandle = < 0x135 >;
		};

		test-thmzone {
			polling-delay-passive = < 0x64 >;
			polling-delay = < 0x3e8 >;
			sustainable-power = < 0xbb8 >;
			thermal-sensors = < 0xb4 0x0c >;
			phandle = < 0x136 >;

			trips {

				trip-point@0 {
					temperature = < 0x11170 >;
					hysteresis = < 0x3e8 >;
					type = "passive";
					phandle = < 0x137 >;
				};

				trip-point@1 {
					temperature = < 0x14c08 >;
					hysteresis = < 0x3e8 >;
					type = "passive";
					phandle = < 0xb5 >;
				};

				bia_crit {
					temperature = < 0x1adb0 >;
					hysteresis = < 0x7d0 >;
					type = "critical";
					phandle = < 0x138 >;
				};
			};

			cooling-maps {

				map0 {
					trip = < 0xb5 >;
					contribution = < 0x400 >;
					cooling-device = < 0xb1 0xffffffff 0xffffffff >;
				};

				map1 {
					trip = < 0xb5 >;
					contribution = < 0x2a2 >;
					cooling-device = < 0xb2 0xffffffff 0xffffffff >;
				};
			};
		};
	};

	cooling-devices {

		cluster0-cooling {
			compatible = "sprd,cluster-cooling";
			#cooling-cells = < 0x02 >;
			sprd,efuse-block7 = < 0x07 >;
			sprd,efuse-block15 = < 0x0f >;
			sprd,leak-core = < 0x02 0x55 0x74d >;
			sprd,leak-cluster = < 0x02 0x55 0x9dc >;
			sprd,core-temp-scale = < 0x1d 0xfffff7cc 0x186a0 0xfff72660 >;
			sprd,core-voltage-scale = < 0xc9 0xffffff57 0x53 0xfffffff0 >;
			sprd,cluster-temp-scale = < 0x1d 0xfffff7cc 0x186a0 0xfff72660 >;
			sprd,cluster-voltage-scale = < 0xc9 0xffffff57 0x53 0xfffffff0 >;
			sprd,efuse-switch = < 0x00 >;
			sprd,hotplug-period = < 0x0a >;
			sprd,min-cpufreq = < 0xbb800 >;
			sprd,min-cpunum = < 0x04 >;
			sprd,core-base = < 0x960 >;
			sprd,cluster-base = < 0xf82 >;
			sprd,dynamic-core = < 0x3ef 0x3e8 0x3e8 >;
			sprd,dynamic-cluster = < 0x2eb 0x3e8 0x3e8 >;
			phandle = < 0xb1 >;
		};

		cluster1-cooling {
			compatible = "sprd,cluster-cooling";
			#cooling-cells = < 0x02 >;
			sprd,efuse-block7 = < 0x07 >;
			sprd,efuse-block15 = < 0x0f >;
			sprd,leak-core = < 0x08 0x55 0x7c0 >;
			sprd,leak-cluster = < 0x08 0x55 0x810 >;
			sprd,core-temp-scale = < 0x1d 0xfffff7cc 0x186a0 0xfff72660 >;
			sprd,core-voltage-scale = < 0xc9 0xffffff57 0x53 0xfffffff0 >;
			sprd,cluster-temp-scale = < 0x1d 0xfffff7cc 0x186a0 0xfff72660 >;
			sprd,cluster-voltage-scale = < 0xc9 0xffffff57 0x53 0xfffffff0 >;
			sprd,efuse-switch = < 0x00 >;
			sprd,hotplug-period = < 0x0a >;
			sprd,min-cpufreq = < 0xbb800 >;
			sprd,min-cpunum = < 0x00 >;
			sprd,core-base = < 0x105e >;
			sprd,cluster-base = < 0xf82 >;
			sprd,dynamic-core = < 0x600 0x3e8 0x3e8 >;
			sprd,dynamic-cluster = < 0x2eb 0x3e8 0x3e8 >;
			phandle = < 0xb2 >;
		};
	};

	gpu-cooling-devices {

		gpu-cooling0 {
			compatible = "sprd,mali-power-model";
			#cooling-cells = < 0x02 >;
			sprd,efuse-block7 = < 0x07 >;
			sprd,efuse-block15 = < 0x0f >;
			sprd,leak-core = < 0x02 0x55 0x74d >;
			sprd,leak-cluster = < 0x02 0x55 0x9dc >;
			sprd,temp-scale = < 0x12c 0xffff8eb8 0x16c038 0xff2af4f0 >;
			sprd,voltage-scale = < 0xfffff9a3 0x19e3 0xffffe529 0x8ae >;
			sprd,hotplug-period = < 0x00 >;
			sprd,core-base = < 0x3c6 >;
			sprd,cluster-base = < 0x3c6 >;
			sprd,dynamic-core = < 0x179e 0x300 0x384 >;
			sprd,dynamic-cluster = < 0x17b0 0x300 0x384 >;
			phandle = < 0x139 >;
		};
	};

	display-subsystem {
		compatible = "sprd,display-subsystem";
		ports = < 0xb6 >;
		gsp = < 0xb7 >;
	};

	scene-frequency {
		compatible = "sprd,dfs";
		freq-num = < 0x08 >;
		info-socdump-enable-flag = < 0x01 >;
		phandle = < 0x13a >;
	};

	chosen {
		stdout-path = "/soc/ap-apb/serial@70100000";
		bootargs = "earlycon=sprd_serial,0x70100000,115200n8 console=ttyS1,115200n8 loglevel=1 init=/init root=/dev/ram0 rw printk.devkmsg=on androidboot.boot_devices=soc/soc:ap-ahb/20600000.sdio swiotlb=1";
		phandle = < 0x13b >;
	};

	reserved-memory {
		#address-cells = < 0x02 >;
		#size-cells = < 0x02 >;
		ranges;
		phandle = < 0x13c >;

		sysdumpinfo-mem@80001000 {
			reg = < 0x00 0x80001000 0x00 0x1000 >;
			phandle = < 0x13d >;
		};

		rebootescrow@0x81ff0000 {
			no-map;
			reg = < 0x00 0x81ff0000 0x00 0x10000 >;
		};

		wcn-mem@84000000 {
			reg = < 0x00 0x84000000 0x00 0x300000 >;
			phandle = < 0x9c >;
		};

		gnss-mem@84300000 {
			reg = < 0x00 0x84300000 0x00 0x15b000 >;
			phandle = < 0xa3 >;
		};

		iq-mem@84d80000 {
			compatible = "sprd,iq-mem";
			reg = < 0x00 0x84d80000 0x00 0x4000000 >;
			phandle = < 0xb8 >;
		};

		sipc-mem@88d80000 {
			reg = < 0x00 0x88d80000 0x00 0x880000 >;
			phandle = < 0x13e >;
		};

		cp-modem@89600000 {
			reg = < 0x00 0x89600000 0x00 0x4a80000 >;
			phandle = < 0x13f >;
		};

		sml-mem@94000000 {
			reg = < 0x00 0x94000000 0x00 0x40000 >;
			phandle = < 0x140 >;
		};

		tos-mem@94040000 {
			reg = < 0x00 0x94040000 0x00 0x1fc0000 >;
			phandle = < 0x141 >;
		};

		sh-mem@96000000 {
			reg = < 0x00 0x96000000 0x00 0x100000 >;
			phandle = < 0xbc >;
		};

		ramoops@fff80000 {
			compatible = "ramoops";
			reg = < 0x00 0xfff80000 0x00 0x40000 >;
			record-size = < 0x8000 >;
			console-size = < 0x8000 >;
			pmsg-size = < 0x8000 >;
			phandle = < 0x142 >;
		};
	};

	sprd-iq {
		compatible = "sprd,iq";
		sprd,region = < 0xb8 >;
		sprd,mapping-offs = < 0x00 >;
	};

	sprd-map-user {
		compatible = "sprd,map-user";
	};

	sprd-wlan {
		compatible = "sprd,sp9863a";
	};

	rebootescrow@0 {
		compatible = "pmem-region";
		reg = < 0x00 0x81ff0000 0x00 0x10000 >;
	};

	sprd-sensorhub {
		compatible = "sprd,sharkl3-sensorhub\0sprd,sensor-hub";
		phandle = < 0x143 >;
	};

	autotest {
		compatible = "sprd,autotest";
		sprd,pinctrl = < 0xb9 >;
		phandle = < 0x144 >;
	};

	extcon-gpio {
		compatible = "linux,extcon-usb-gpio";
		vbus-gpio = < 0x3b 0x00 0x00 >;
		id-gpio = < 0xba 0x04 0x00 >;
		io-channels = < 0x10 0x07 >;
		io-channel-names = "usb_id_det";
		phandle = < 0x12 >;
	};

	interrupt-controller {
		compatible = "android,CustomIPI";
		#interrupt-cells = < 0x01 >;
		interrupt-controller;
		phandle = < 0xbb >;
	};

	trusty {
		compatible = "android,trusty-smc-v1";

		irq {
			compatible = "android,trusty-irq-v1";
			interrupt-templates = < 0xbb 0x00 0x01 0x01 0x01 0x00 0x01 0x01 0x00 0x00 >;
			interrupt-ranges = < 0x00 0x0f 0x00 0x10 0x1f 0x01 0x20 0xdf 0x02 >;
		};

		virtio {
			compatible = "android,trusty-virtio-v1";
		};

		log {
			compatible = "android,trusty-log-v1";
		};

		sprd-tshm {
			compatible = "sprd,tshm";
			memory-region = < 0xbc >;
		};
	};

	__symbols__ {
		soc = "/soc";
		modem_dbg_log = "/soc/modem-dbg-log@1000c000";
		ap_ahb_regs = "/soc/syscon@20e00000";
		pub_apb_regs = "/soc/syscon@300e0000";
		pub_ahb_regs = "/soc/syscon@300f0000";
		aon_mailbox = "/soc/mailbox@400a0000";
		aon_intc_regs = "/soc/syscon@40200000";
		pmu_apb_regs = "/soc/syscon@402b0000";
		disp_pd = "/soc/power-domain@402b0058";
		aon_apb_regs = "/soc/syscon@402e0000";
		anlg_phy_g1_regs = "/soc/syscon@40350000";
		anlg_phy_g2_regs = "/soc/syscon@40353000";
		anlg_phy_g4_regs = "/soc/syscon@40359000";
		anlg_phy_g5_regs = "/soc/syscon@4035c000";
		anlg_phy_g7_regs = "/soc/syscon@40363000";
		anlg_wrap_wcn_regs = "/soc/syscon@40366000";
		wcn_regs = "/soc/syscon@403a0000";
		mm_ahb_regs = "/soc/syscon@60800000";
		mm_vsp_ahb_regs = "/soc/syscon@62000000";
		ap_apb_regs = "/soc/syscon@71300000";
		ap_intc0_regs = "/soc/syscon@40500000";
		ap_intc1_regs = "/soc/syscon@40510000";
		ap_intc2_regs = "/soc/syscon@40520000";
		ap_intc3_regs = "/soc/syscon@40530000";
		ap_intc4_regs = "/soc/syscon@40540000";
		ap_intc5_regs = "/soc/syscon@40550000";
		uart0 = "/soc/ap-apb/serial@70000000";
		uart1 = "/soc/ap-apb/serial@70100000";
		uart2 = "/soc/ap-apb/serial@70200000";
		uart3 = "/soc/ap-apb/serial@70300000";
		uart4 = "/soc/ap-apb/serial@70400000";
		i2c0 = "/soc/ap-apb/i2c@70500000";
		i2c1 = "/soc/ap-apb/i2c@70600000";
		i2c2 = "/soc/ap-apb/i2c@70700000";
		i2c3 = "/soc/ap-apb/i2c@70800000";
		i2c4 = "/soc/ap-apb/i2c@70900000";
		spi0 = "/soc/ap-apb/spi@70a00000";
		spi1 = "/soc/ap-apb/spi@70b00000";
		spi2 = "/soc/ap-apb/spi@70c00000";
		i2s0 = "/soc/ap-apb/i2s@70d00000";
		spi3 = "/soc/ap-apb/spi@71400000";
		i2c5 = "/soc/ap-apb/i2c@71500000";
		i2c6 = "/soc/ap-apb/i2c@71600000";
		ap_dma = "/soc/ap-ahb/dma-controller@20100000";
		usb = "/soc/ap-ahb/usb@20200000";
		hsphy = "/soc/ap-ahb/hsphy@20e00000";
		sdio3 = "/soc/ap-ahb/sdio@20600000";
		sdio0 = "/soc/ap-ahb/sdio@20300000";
		sprd_audio_codec_dig = "/soc/aon/audio-codec@40000000";
		vbc = "/soc/aon/vbc@40020000";
		aon_dma = "/soc/aon/dma-controller@40100000";
		eic_debounce = "/soc/aon/gpio@40210000";
		eic_latch = "/soc/aon/gpio@40210080";
		eic_async = "/soc/aon/gpio@402100a0";
		eic_sync = "/soc/aon/gpio@402100c0";
		aon_systimer = "/soc/aon/timer@40230000";
		aon_sysfrt = "/soc/aon/timer@40040000";
		ap_efuse = "/soc/aon/efuse@40240000";
		gthm_delta = "/soc/aon/efuse@40240000/gthm-delta@21";
		cthm_sign = "/soc/aon/efuse@40240000/cthm-sign@22";
		cthm_ratio = "/soc/aon/efuse@40240000/cthm-ratio@22";
		cthm_delta = "/soc/aon/efuse@40240000/cthm-delta@23";
		wcn_alpha = "/soc/aon/efuse@40240000/wcn-alpha@14";
		wcn_beta = "/soc/aon/efuse@40240000/wcn-beta@18";
		wcn_gamma = "/soc/aon/efuse@40240000/wcn-gamma@1c";
		wcn_delta = "/soc/aon/efuse@40240000/wcn-delta@20";
		dvfs_bin_dsu = "/soc/aon/efuse@40240000/dvfs-bin-dsu@a";
		dvfs_bin_cpu0 = "/soc/aon/efuse@40240000/dvfs-bin-cpu0@9";
		dvfs_bin_cpu1 = "/soc/aon/efuse@40240000/dvfs-bin-cpu1@9";
		pwms = "/soc/aon/pwm@40260000";
		pin_controller = "/soc/aon/pinctrl@402a0000";
		vbc_iis1_0 = "/soc/aon/pinctrl@402a0000/iismtx-inf0-8";
		ap_iis0_0 = "/soc/aon/pinctrl@402a0000/iismtx-inf0-0";
		ap_iis1_0 = "/soc/aon/pinctrl@402a0000/iismtx-inf0-1";
		tgdsp_iis0_0 = "/soc/aon/pinctrl@402a0000/iismtx-inf0-4";
		tgdsp_iis1_0 = "/soc/aon/pinctrl@402a0000/iismtx-inf0-5";
		pubcp_iis0_0 = "/soc/aon/pinctrl@402a0000/iismtx-inf0-3";
		vbc_iis1_3 = "/soc/aon/pinctrl@402a0000/iismtx-inf3-8";
		ap_iis0_3 = "/soc/aon/pinctrl@402a0000/iismtx-inf3-0";
		tgdsp_iis0_3 = "/soc/aon/pinctrl@402a0000/iismtx-inf3-4";
		tgdsp_iis1_3 = "/soc/aon/pinctrl@402a0000/iismtx-inf3-5";
		pubcp_iis0_3 = "/soc/aon/pinctrl@402a0000/iismtx-inf3-3";
		wcn_iis0_3 = "/soc/aon/pinctrl@402a0000/iismtx-inf3-11";
		vbc_iis1_4 = "/soc/aon/pinctrl@402a0000/iismtx-inf4-8";
		ap_iis0_4 = "/soc/aon/pinctrl@402a0000/iismtx-inf4-0";
		tgdsp_iis0_4 = "/soc/aon/pinctrl@402a0000/iismtx-inf4-4";
		tgdsp_iis1_4 = "/soc/aon/pinctrl@402a0000/iismtx-inf4-5";
		pubcp_iis0_4 = "/soc/aon/pinctrl@402a0000/iismtx-inf4-3";
		wcn_iis0_4 = "/soc/aon/pinctrl@402a0000/iismtx-inf4-11";
		iis_loop_3_4_enable = "/soc/aon/pinctrl@402a0000/iismtx-inf3-inf4-loop-1";
		iis_loop_3_4_disable = "/soc/aon/pinctrl@402a0000/iismtx-inf3-inf4-loop-0";
		ap_gpio = "/soc/aon/gpio-controller@402c0000";
		gpu_thm = "/soc/aon/gpu-thm@402f0000";
		cpu_thm = "/soc/aon/cpu-thm@40390000";
		test_sensor = "/soc/aon/test-sensor@12";
		hwlock = "/soc/aon/hwspinlock@40060000";
		i2c7 = "/soc/aon/i2c@40080000";
		fan53555_dcdc = "/soc/aon/i2c@40080000/regulator@60";
		sprd_hwdvfs = "/soc/aon/hwdvfs@40300000";
		sprd_swdvfs = "/soc/aon/sprd-swdvfs";
		djtag = "/soc/aon/djtag@40340000";
		adi_bus = "/soc/aon/spi@41800000";
		sc2721_pmic = "/soc/aon/spi@41800000/pmic@0";
		pmic_wdt = "/soc/aon/spi@41800000/pmic@0/watchdog@40";
		pmic_eic = "/soc/aon/spi@41800000/pmic@0/gpio-controller@280";
		pmic_flash = "/soc/aon/spi@41800000/pmic@0/flash@2a8";
		fgu_calib = "/soc/aon/spi@41800000/pmic@0/efuse@300/calib@6";
		adc_bcal = "/soc/aon/spi@41800000/pmic@0/efuse@300/calib@24";
		adc_scal = "/soc/aon/spi@41800000/pmic@0/efuse@300/calib@26";
		typec_cc1_cal = "/soc/aon/spi@41800000/pmic@0/efuse@300/calib@d1";
		typec_cc2_cal = "/soc/aon/spi@41800000/pmic@0/efuse@300/calib@d2";
		efuse_blk0 = "/soc/aon/spi@41800000/pmic@0/efuse@300/calib@0";
		efuse_blk14 = "/soc/aon/spi@41800000/pmic@0/efuse@300/calib@28";
		efuse_blk16 = "/soc/aon/spi@41800000/pmic@0/efuse@300/calib@2c";
		fchg_calib = "/soc/aon/spi@41800000/pmic@0/efuse@300/calib@12";
		pmic_typec = "/soc/aon/spi@41800000/pmic@0/typec@380";
		pmic_adc = "/soc/aon/spi@41800000/pmic@0/adc@400";
		pmic_fchg = "/soc/aon/spi@41800000/pmic@0/fchg@900";
		pmic_fgu = "/soc/aon/spi@41800000/pmic@0/fgu@a00";
		sprd_audio_codec_ana = "/soc/aon/spi@41800000/pmic@0/audio-codec@700";
		vddcpu = "/soc/aon/spi@41800000/pmic@0/power-controller@c00/DCDC_CPU";
		vddcore = "/soc/aon/spi@41800000/pmic@0/power-controller@c00/DCDC_CORE";
		vddmem = "/soc/aon/spi@41800000/pmic@0/power-controller@c00/DCDC_MEM";
		vddgen = "/soc/aon/spi@41800000/pmic@0/power-controller@c00/DCDC_GEN";
		vddcama = "/soc/aon/spi@41800000/pmic@0/power-controller@c00/LDO_VDDCAMA";
		vddcammot = "/soc/aon/spi@41800000/pmic@0/power-controller@c00/LDO_VDDCAMMOT";
		vddsim2 = "/soc/aon/spi@41800000/pmic@0/power-controller@c00/LDO_VDDSIM2";
		vddemmccore = "/soc/aon/spi@41800000/pmic@0/power-controller@c00/LDO_VDDEMMCCORE";
		vddsdcore = "/soc/aon/spi@41800000/pmic@0/power-controller@c00/LDO_VDDSDCORE";
		vddsdio = "/soc/aon/spi@41800000/pmic@0/power-controller@c00/LDO_VDDSDIO";
		vdd28 = "/soc/aon/spi@41800000/pmic@0/power-controller@c00/LDO_VDD28";
		vddwifipa = "/soc/aon/spi@41800000/pmic@0/power-controller@c00/LDO_VDDWIFIPA";
		vdddcxo = "/soc/aon/spi@41800000/pmic@0/power-controller@c00/LDO_VDDDCXO";
		vddusb33 = "/soc/aon/spi@41800000/pmic@0/power-controller@c00/LDO_VDDUSB33";
		vddcamd = "/soc/aon/spi@41800000/pmic@0/power-controller@c00/LDO_VDDCAMD";
		vddcon = "/soc/aon/spi@41800000/pmic@0/power-controller@c00/LDO_VDDCON";
		vddcamio = "/soc/aon/spi@41800000/pmic@0/power-controller@c00/LDO_VDDCAMIO";
		vdd18 = "/soc/aon/spi@41800000/pmic@0/power-controller@c00/LDO_VDD18";
		vddrf18 = "/soc/aon/spi@41800000/pmic@0/power-controller@c00/LDO_VDDRF18";
		vddrf125 = "/soc/aon/spi@41800000/pmic@0/power-controller@c00/LDO_VDDRF125";
		vddldomem = "/soc/aon/spi@41800000/pmic@0/power-controller@c00/LDO_VDDLDOMEM";
		vddkpled = "/soc/aon/spi@41800000/pmic@0/power-controller@c00/LDO_VDDKPLED";
		cam_domain = "/soc/mm/cam-domain";
		gpu = "/soc/mm/gpu@60000000";
		dpu = "/soc/mm/dpu@63000000";
		dpu_port = "/soc/mm/dpu@63000000/port";
		dpu_out = "/soc/mm/dpu@63000000/port/endpoint";
		gsp_core0 = "/soc/mm/gsp@63000000";
		iommu_dispc = "/soc/mm/iommu@63000800";
		vsp = "/soc/mm/video-codec@62200000";
		iommu_vsp = "/soc/mm/iommu@62200000";
		jpg = "/soc/mm/jpeg-codec@62300000";
		iommu_jpg = "/soc/mm/iommu@62300300";
		dsi = "/soc/mm/dsi@63100000";
		dsi_out = "/soc/mm/dsi@63100000/ports/port@0/endpoint";
		dsi_in = "/soc/mm/dsi@63100000/ports/port@1/endpoint";
		panel = "/soc/mm/dsi@63100000/panel";
		panel_in = "/soc/mm/dsi@63100000/panel/port@1/endpoint";
		dphy = "/soc/mm/dphy";
		dphy_out = "/soc/mm/dphy/port@0/endpoint";
		dphy_in = "/soc/mm/dphy/port@1/endpoint";
		mipi_csi_phy0 = "/soc/mm/mipi-csi-phy0";
		mipi_csi_phy1 = "/soc/mm/mipi-csi-phy1";
		mipi_csi_phy2 = "/soc/mm/mipi-csi-phy2";
		mipi_csi_phy0_m = "/soc/mm/mipi-csi-phy0-s";
		mipi_csi_phy0_s = "/soc/mm/mipi-csi-phy0-m";
		mipi_csi_phy0_s1 = "/soc/mm/mipi-csi-phy0-m1";
		dcam = "/soc/mm/dcam@60a00000";
		iommu_dcam = "/soc/mm/iommu@60a0c000";
		isp = "/soc/mm/isp@60b00000";
		iommu_isp = "/soc/mm/iommu@60bffc00";
		csi0 = "/soc/mm/csi@60c00000";
		csi1 = "/soc/mm/csi@60d00000";
		csi2 = "/soc/mm/csi@60e00000";
		cpp = "/soc/mm/cpp@62400000";
		iommu_cpp = "/soc/mm/iommu@62400200";
		dmc_controller = "/soc/pub/dmc-controller@30000000";
		ptm_trace = "/soc/pub/ptm@30010000";
		dmc_mpu = "/soc/pub/dmc-mpu@300e0000";
		pmu_gate = "/soc/pmu-gate";
		pll = "/soc/pll";
		mpll = "/soc/mpll";
		rpll = "/soc/rpll";
		dpll = "/soc/dpll";
		ap_clk = "/soc/clock-controller@21500000";
		aon_clk = "/soc/clock-controller@402d0000";
		apahb_gate = "/soc/apahb-gate";
		aonapb_gate = "/soc/aonapb-gate";
		mm_clk = "/soc/clock-controller@60900000";
		mm_gate = "/soc/mm-gate";
		vspahb_gate = "/soc/vspahb-gate";
		apapb_gate = "/soc/apapb-gate";
		funnel_soc_out_port0 = "/soc/funnel@10001000/ports/port@0/endpoint";
		funnel_soc_in_port0 = "/soc/funnel@10001000/ports/port@1/endpoint";
		soc_etb = "/soc/etb@10003000";
		etb_in = "/soc/etb@10003000/port/endpoint";
		funnel_little_out_port0 = "/soc/funnel@12001000/ports/port@0/endpoint";
		funnel_little_in_port0 = "/soc/funnel@12001000/ports/port@1/endpoint";
		funnel_little_in_port1 = "/soc/funnel@12001000/ports/port@2/endpoint";
		funnel_little_in_port2 = "/soc/funnel@12001000/ports/port@3/endpoint";
		funnel_little_in_port3 = "/soc/funnel@12001000/ports/port@4/endpoint";
		etf_little_out = "/soc/etf@12002000/port@0/endpoint";
		etf_little_in = "/soc/etf@12002000/port@1/endpoint";
		etf_big_out = "/soc/etf@12003000/port@0/endpoint";
		etf_big_in = "/soc/etf@12003000/port@1/endpoint";
		funnel_ca55_out_port0 = "/soc/funnel@12004000/ports/port@0/endpoint";
		funnel_ca55_in_port0 = "/soc/funnel@12004000/ports/port@1/endpoint";
		funnel_ca55_in_port1 = "/soc/funnel@12004000/ports/port@2/endpoint";
		funnel_big_out_port0 = "/soc/funnel@12005000/ports/port@0/endpoint";
		funnel_big_in_port0 = "/soc/funnel@12005000/ports/port@1/endpoint";
		funnel_big_in_port1 = "/soc/funnel@12005000/ports/port@2/endpoint";
		funnel_big_in_port2 = "/soc/funnel@12005000/ports/port@3/endpoint";
		funnel_big_in_port3 = "/soc/funnel@12005000/ports/port@4/endpoint";
		etm0 = "/soc/etm@13040000";
		etm0_out = "/soc/etm@13040000/port/endpoint";
		etm1 = "/soc/etm@13140000";
		etm1_out = "/soc/etm@13140000/port/endpoint";
		etm2 = "/soc/etm@13240000";
		etm2_out = "/soc/etm@13240000/port/endpoint";
		etm3 = "/soc/etm@13340000";
		etm3_out = "/soc/etm@13340000/port/endpoint";
		etm4 = "/soc/etm@13440000";
		etm4_out = "/soc/etm@13440000/port/endpoint";
		etm5 = "/soc/etm@13540000";
		etm5_out = "/soc/etm@13540000/port/endpoint";
		etm6 = "/soc/etm@13640000";
		etm6_out = "/soc/etm@13640000/port/endpoint";
		etm7 = "/soc/etm@13740000";
		etm7_out = "/soc/etm@13740000/port/endpoint";
		ap_etb = "/soc/apetb";
		ext_26m = "/ext-26m";
		ext_13m = "/ext-13m";
		ext_6m5 = "/ext-6m5";
		ext_4m3 = "/ext-4m3";
		ext_4m = "/ext-4m";
		ext_250k = "/ext-250k";
		ext_32k = "/ext-32k";
		ext_1k = "/ext-1k";
		ext_1m = "/ext-1m";
		ext_2m = "/ext-2m";
		ext_rc0_4m = "/ext-rc0-4m";
		clk_pad = "/clk-pad";
		rco_100m = "/rco-100m";
		sprd_pcm = "/sprd-pcm-audio";
		vaudio = "/vaudio";
		sprd_pcm_iis = "/sprd-pcm-iis";
		CPU0 = "/cpus/cpu@0";
		CPU1 = "/cpus/cpu@100";
		CPU2 = "/cpus/cpu@200";
		CPU3 = "/cpus/cpu@300";
		CPU4 = "/cpus/cpu@400";
		CPU5 = "/cpus/cpu@500";
		CPU6 = "/cpus/cpu@600";
		CPU7 = "/cpus/cpu@700";
		CPU_COST_0 = "/energy-costs/core-cost0";
		CPU_COST_1 = "/energy-costs/core-cost1";
		CLUSTER_COST_0 = "/energy-costs/cluster-cost0";
		CLUSTER_COST_1 = "/energy-costs/cluster-cost1";
		CORE_PD = "/idle-states/core_pd";
		cpufreq_clus0 = "/cpufreq-clus0";
		cpufreq_clus1 = "/cpufreq-clus1";
		cpufreq_fcm = "/cpufreq-fcm";
		gic = "/interrupt-controller@14000000";
		v2m_0 = "/interrupt-controller@14000000/v2m@0";
		power = "/power-debug";
		gsp = "/sprd-gsp";
		wcn_btwf = "/cpwcn_btwf";
		wcn_gnss = "/cpwcn_gnss";
		sipc2 = "/wcn_sipc/sipc@84180000";
		sipc3 = "/wcn_sipc/sipc@8441b000";
		scproc_pubpm = "/scproc-pubcp/scproc@800000";
		scproc_pubcp = "/scproc-pubcp/scproc@f000";
		sipc0 = "/sprd-sipc/sipc@88d80000";
		sipc1 = "/sprd-sipc/sipc@d000";
		seth_ch7 = "/seth@0";
		seth_ch8 = "/seth@1";
		seth_ch9 = "/seth@2";
		seth_ch18 = "/seth@3";
		seth_ch19 = "/seth@4";
		seth_ch20 = "/seth@5";
		seth_ch24 = "/seth@6";
		seth_ch25 = "/seth@7";
		seth_ch26 = "/seth@8";
		seth_ch27 = "/seth@9";
		seth_ch28 = "/seth@10";
		seth_ch29 = "/seth@11";
		seth_ch30 = "/seth@12";
		seth_ch31 = "/seth@13";
		sprd_headset = "/sprd-headset";
		sound_vbc_r1p0v3_sprd_codec = "/sound@0";
		sound_sprd_ap_alliis = "/sound@1";
		memory = "/memory";
		vbmeta = "/firmware/android/vbmeta";
		ion = "/ion";
		thm_zone = "/thermal-zones";
		cpu_thmzone = "/thermal-zones/cpu-thmzone";
		cpu_threshold = "/thermal-zones/cpu-thmzone/trips/trip-point@0";
		cpu_target = "/thermal-zones/cpu-thmzone/trips/trip-point@1";
		cpu_crit = "/thermal-zones/cpu-thmzone/trips/bia_crit";
		gpu_thmzone = "/thermal-zones/gpu-thmzone";
		test_thmzone = "/thermal-zones/test-thmzone";
		cpu_virtual_threshold = "/thermal-zones/test-thmzone/trips/trip-point@0";
		cpu_virtual_target = "/thermal-zones/test-thmzone/trips/trip-point@1";
		cpu_virtual_crit = "/thermal-zones/test-thmzone/trips/bia_crit";
		cluster0_cooling = "/cooling-devices/cluster0-cooling";
		cluster1_cooling = "/cooling-devices/cluster1-cooling";
		gpu_cooling0 = "/gpu-cooling-devices/gpu-cooling0";
		ddr_dfs = "/scene-frequency";
		chosen = "/chosen";
		reserved_memory = "/reserved-memory";
		sysdump_reserved = "/reserved-memory/sysdumpinfo-mem@80001000";
		wcn_reserved = "/reserved-memory/wcn-mem@84000000";
		gnss_reserved = "/reserved-memory/gnss-mem@84300000";
		iq_reserved = "/reserved-memory/iq-mem@84d80000";
		smem_reserved = "/reserved-memory/sipc-mem@88d80000";
		cp_reserved = "/reserved-memory/cp-modem@89600000";
		sml_reserved = "/reserved-memory/sml-mem@94000000";
		tos_reserved = "/reserved-memory/tos-mem@94040000";
		tos_shm_reserved = "/reserved-memory/sh-mem@96000000";
		pstore_reserved = "/reserved-memory/ramoops@fff80000";
		sensorhub = "/sprd-sensorhub";
		autotest = "/autotest";
		extcon_gpio = "/extcon-gpio";
		ipi = "/interrupt-controller";
	};
};
